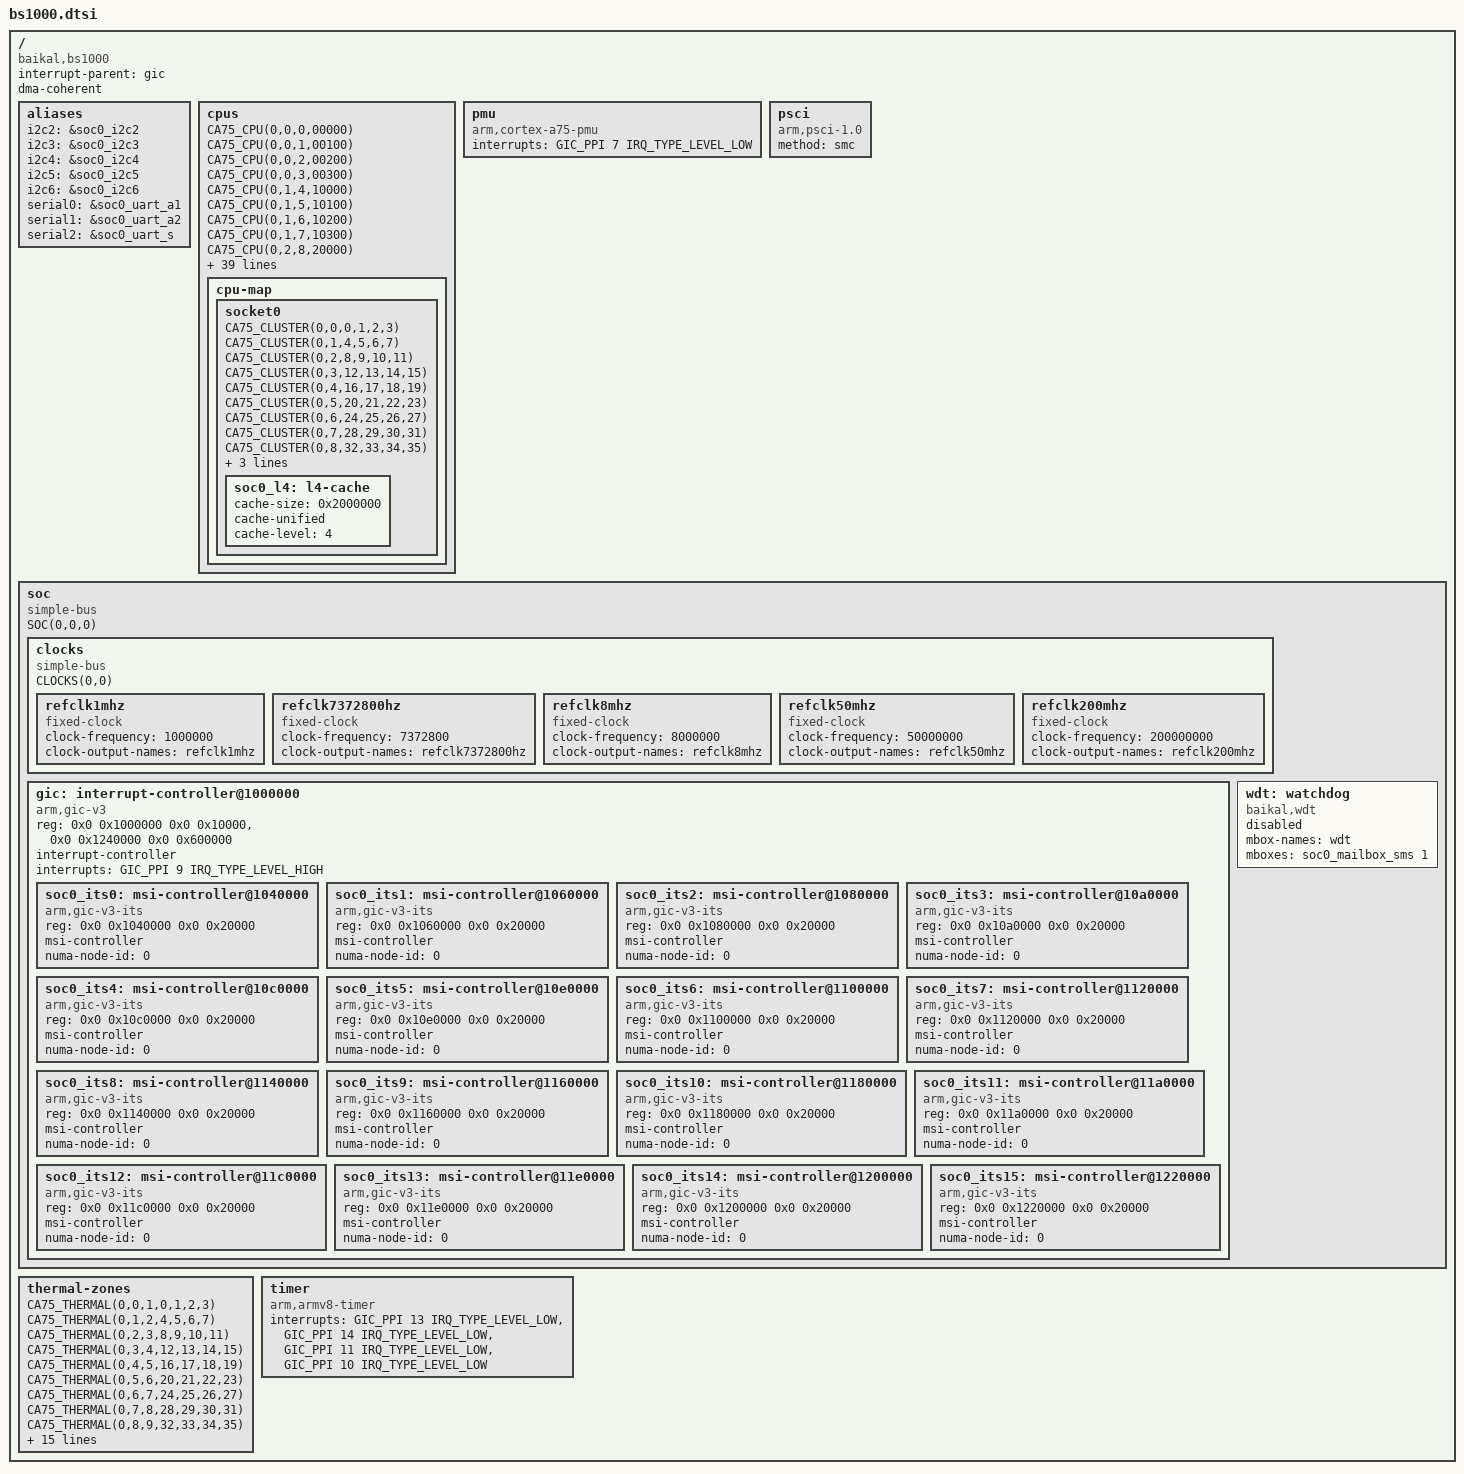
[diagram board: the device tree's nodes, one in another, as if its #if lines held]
// SPDX-License-Identifier: GPL-2.0
/*
 * Device tree include file for BE-S1000 SoC
 * Copyright (C) 2021-2025 Baikal Electronics, JSC
 */

#include <dt-bindings/gpio/gpio.h>
#include <dt-bindings/interrupt-controller/arm-gic.h>
#include <dt-bindings/thermal/thermal.h>

#define CA75_CLUSTER(chip, group, a,b,c,d)				\
	cluster##group {						\
		core0 {							\
			cpu = <&cpu##a>;				\
		};							\
		core1 {							\
			cpu = <&cpu##b>;				\
		};							\
		core2 {							\
			cpu = <&cpu##c>;				\
		};							\
		core3 {							\
			cpu = <&cpu##d>;				\
		};							\
		soc##chip##_l3_##group: l3-cache {			\
			compatible = "cache";				\
			cache-size = <0x200000>;			\
			cache-line-size = <64>;				\
			cache-sets = <2048>;				\
			cache-unified;					\
			cache-level = <3>;				\
			next-level-cache = <&soc##chip##_l4>;		\
		};							\
		cpu_opp_table##chip##group: opp_table {			\
			compatible = "operating-points-v2";		\
			opp-shared;					\
			opp-1800000000 {				\
				opp-hz = /bits/ 64 <1800000000>;	\
			};						\
			opp-1900000000 {				\
				opp-hz = /bits/ 64 <1900000000>;	\
			};						\
			opp-2000000000 {				\
				opp-hz = /bits/ 64 <2000000000>;	\
			};						\
		};							\
	}

#define CA75_CPU(chip, group, core, affinity)					\
	cpu##core: cpu@##chip##000##affinity {					\
		device_type = "cpu";						\
		compatible = "arm,cortex-a75";					\
		reg = <0x##chip 0x##affinity>;					\
		enable-method = "psci";						\
		i-cache-size = <0x10000>;					\
		i-cache-line-size = <64>;					\
		i-cache-sets = <256>;						\
		d-cache-size = <0x10000>;					\
		d-cache-line-size = <64>;					\
		d-cache-sets = <64>;						\
		next-level-cache = <&l2_##core>;				\
		operating-points-v2 = <&cpu_opp_table##chip##group>;		\
		clocks = <&soc##chip##_ca75_##group##_cmu1_pll>;		\
		numa-node-id = <chip>;						\
		#cooling-cells = <2>; /* min followed by max */			\
		l2_##core: l2-cache {						\
			compatible = "cache";					\
			cache-size = <0x80000>;					\
			cache-line-size = <64>;					\
			cache-sets = <1024>;					\
			cache-unified;						\
			cache-level = <2>;					\
			next-level-cache = <&soc##chip##_l3_##group>;		\
		};								\
	}

#define CLK_TYPE_REFCLK	1 /* fout = 25 MHz or 100 MHz		*/
#define CLK_TYPE_PLL	2 /* fout = 2 * fref * NF / (NR * OD)	*/
#define CLK_TYPE_CLKCH	3 /* fout = fref / (VAL_CLKDIV + 1)	*/
#define CLK_TYPE_CLKEN	4 /* fout = fref / DIV_VAL		*/
#define CLK_TYPE_CLKDIV	5 /* fout = fref / 2^(DIV_VAL - 1)	*/

#define STRINGIFY2( x) #x
#define STRINGIFY(x) STRINGIFY2(x)

#define CA75_CLOCKS(chip, group, hbase, lbase)						\
	/* pll */									\
	soc##chip##_ca75_##group##_cmu0_pll:						\
	soc##chip##_ca75_##group##_cmu0_pll {						\
		compatible = "baikal,bs1000-cmu";					\
		reg = <0x##hbase 0x##lbase>;						\
		type = <CLK_TYPE_PLL>;							\
		clocks = <&soc##chip##_clk_ref>;					\
		#clock-cells = <0>;							\
		clock-output-names = "ca75_pll0";					\
	};										\
	soc##chip##_ca75_##group##_cmu1_pll:						\
	soc##chip##_ca75_##group##_cmu1_pll {						\
		compatible = "baikal,bs1000-cmu";					\
		reg = <0x##hbase (0x##lbase + 0x10000)>;				\
		type = <CLK_TYPE_PLL>;							\
		clocks = <&soc##chip##_clk_ref>;					\
		#clock-cells = <0>;							\
		clock-output-names = "ca75_pll1";					\
		clock-frequency = <2000000000>;						\
	};										\
	/* clkch */									\
	soc##chip##_ca75_##group##_cmu0_clkch:						\
	soc##chip##_ca75_##group##_cmu0_clkch {						\
		compatible = "baikal,bs1000-cmu";					\
		reg = <0x##hbase (0x##lbase + 0x100)>;					\
		type = <CLK_TYPE_CLKCH>;						\
		clocks = <&soc##chip##_ca75_##group##_cmu0_pll>;			\
		#clock-cells = <1>;							\
		clock-output-names =							\
			"sclk",		/* 0 */						\
			"periph",	/* 1 */						\
			"pclk",		/* 2 */						\
			"at",		/* 3 */						\
			"gic",		/* 4 */						\
			"cfg_int",	/* 5 */						\
			"cfg_out",	/* 6 */						\
			"bisr",		/* 7 */						\
			"crp";		/* 8 */						\
	};										\
	/* clken */									\
	soc##chip##_ca75_##group##_cmu0_en0:						\
	soc##chip##_ca75_##group##_cmu0_en0 {						\
		compatible = "baikal,bs1000-cmu";					\
		reg = <0x##hbase (0x##lbase + 0x500)>;					\
		type = <CLK_TYPE_CLKEN>;						\
		clocks = <&soc##chip##_ca75_##group##_cmu0_clkch 0>; /* "sclk" */	\
		#clock-cells = <0>;							\
		clock-output-names = "clken";						\
	};										\
	soc##chip##_ca75_##group##_cmu0_en1:						\
	soc##chip##_ca75_##group##_cmu0_en1 {						\
		compatible = "baikal,bs1000-cmu";					\
		reg = <0x##hbase (0x##lbase + 0x510)>;					\
		type = <CLK_TYPE_CLKEN>;						\
		clocks = <&soc##chip##_ca75_##group##_cmu0_clkch 1>; /* "periph" */	\
		#clock-cells = <1>;							\
		clock-output-names =							\
			"cntclken",	/* 0 */						\
			"tsclken";	/* 1 */						\
	};										\
	/* core */									\
	soc##chip##_ca75_##group##_cmu1_core:						\
	soc##chip##_ca75_##group##_cmu1_core {						\
		compatible = "baikal,bs1000-cmu";					\
		reg = <0x##hbase (0x##lbase + 0x10020)>;				\
		type = <CLK_TYPE_CLKDIV>;						\
		clocks = <&soc##chip##_ca75_##group##_cmu1_pll>;			\
		#clock-cells = <1>;							\
		clock-output-names =							\
			"core0",	/* 0 */						\
			"core1",	/* 1 */						\
			"core2",	/* 2 */						\
			"core3";	/* 3 */						\
		clock-frequency =							\
			<2000000000>,							\
			<2000000000>,							\
			<2000000000>,							\
			<2000000000>;							\
	}

#define MM_CLOCKS(chip, mm, num, hbase, lbase, ...)			\
	/* pll */							\
	soc##chip##_##mm##_cmu##num##_pll:				\
	soc##chip##_##mm##_cmu##num##_pll {				\
		compatible = "baikal,bs1000-cmu";			\
		reg = <0x##hbase 0x##lbase>;				\
		type = <CLK_TYPE_PLL>;					\
		clocks = <&soc##chip##_clk_ref>;			\
		#clock-cells = <0>;					\
		clock-output-names = STRINGIFY(mm ## pll); 		\
	};								\
	/* clkch */							\
	soc##chip##_##mm##_cmu##num##_clkch:				\
	soc##chip##_##mm##_cmu##num##_clkch {				\
		compatible = "baikal,bs1000-cmu";			\
		reg = <0x##hbase (0x##lbase + 0x20)>;			\
		type = <CLK_TYPE_CLKCH>;				\
		clocks = <&soc##chip##_##mm##_cmu##num##_pll>;		\
		#clock-cells = <1>;					\
		clock-output-names = __VA_ARGS__;			\
	}

#define CLOCKS(chip, hbase)							\
	/* CLK_REF */								\
	soc##chip##_clk_ref: soc##chip##_clk_ref {				\
		compatible = "baikal,bs1000-cmu";				\
		reg = <0x##hbase 0xdead>;					\
		type = <CLK_TYPE_REFCLK>;					\
		#clock-cells = <0>;						\
		clock-output-names = "clk_ref";					\
	};									\
										\
	CA75_CLOCKS(chip, 0, hbase, 04000000);					\
	CA75_CLOCKS(chip, 1, hbase, 08000000);					\
	CA75_CLOCKS(chip, 2, hbase, 0c000000);					\
	CA75_CLOCKS(chip, 3, hbase, 10000000);					\
	CA75_CLOCKS(chip, 4, hbase, 14000000);					\
	CA75_CLOCKS(chip, 5, hbase, 18000000);					\
	CA75_CLOCKS(chip, 6, hbase, 1c000000);					\
	CA75_CLOCKS(chip, 7, hbase, 20000000);					\
	CA75_CLOCKS(chip, 8, hbase, 24000000);					\
	CA75_CLOCKS(chip, 9, hbase, 28000000);					\
	CA75_CLOCKS(chip, 10,hbase, 2c000000);					\
	CA75_CLOCKS(chip, 11,hbase, 30000000);					\
										\
	/* PCIe */								\
	MM_CLOCKS(chip, pci_0,, hbase, 38000000,				\
		"nic_cfg0m_ssa_x16p0s",		/* 0  */			\
		"nic_cfg1m_ssa_x8p1s",		/* 1  */			\
		"nic_cfg2m_mmu_tcus",		/* 2  */			\
		"nic_cfg3m_ssa_apbs",		/* 3  */			\
		"nic_cfg4m_nic_slv_gpvs",	/* 4  */			\
		"nic_slv0m_ssa_x16p0s",		/* 5  */			\
		"nic_slv1m_ssa_x8p1s",		/* 6  */			\
		"ssa_x16p0m_nic_mstr0s",	/* 7  */			\
		"ssa_x8p1m_nic_mstr1s",		/* 8  */			\
		"nic_mstrm_mmu_tbu0s",		/* 9  */			\
		"a4sw_intern",			/* 10 */			\
		"phy_ref",			/* 11 */			\
		"ssa_aux",			/* 12 */			\
		"ahb2axim_axi2ahbs",		/* 13 */			\
		"ahb2ahbm_outp_ahbs",		/* 14 */			\
		"ssa_x16p0m_cxlas"		/* 15 */			\
	);									\
	MM_CLOCKS(chip, pci_1,, hbase, 3c000000,				\
		"nic_cfg0m_ssa_x16p0s",		/* 0  */			\
		"nic_cfg1m_ssa_x8p1s",		/* 1  */			\
		"nic_cfg2m_mmu_tcus",		/* 2  */			\
		"nic_cfg3m_ssa_apbs",		/* 3  */			\
		"nic_cfg4m_nic_slv_gpvs",	/* 4  */			\
		"nic_slv0m_ssa_x16p0s",		/* 5  */			\
		"nic_slv1m_ssa_x8p1s",		/* 6  */			\
		"ssa_x16p0m_nic_mstr0s",	/* 7  */			\
		"ssa_x8p1m_nic_mstr1s",		/* 8  */			\
		"nic_mstrm_mmu_tbu0s",		/* 9  */			\
		"a4sw_intern",			/* 10 */			\
		"phy_ref",			/* 11 */			\
		"ssa_aux",			/* 12 */			\
		"ahb2axim_axi2ahbs",		/* 13 */			\
		"ahb2ahbm_outp_ahbs",		/* 14 */			\
		"ssa_x16p0m_cxlas"		/* 15 */			\
	);									\
	MM_CLOCKS(chip, pci_2,, hbase, 44000000,				\
		"a", /* 0 */							\
		"b"  /* 1 */							\
	);									\
	MM_CLOCKS(chip, pci_3,, hbase, 48000000,				\
		"a", /* 0 */							\
		"b"  /* 1 */							\
	);									\
	MM_CLOCKS(chip, pci_4,, hbase, 4c000000,				\
		"a", /* 0 */							\
		"b"  /* 1 */							\
	);									\
										\
	/* DDR */								\
	MM_CLOCKS(chip, ddr_0,, hbase, 50000000,				\
		"ddr_ctrl_phy",		/* 0 */					\
		"ddr_axi_slv",		/* 1 */					\
		"ddr_apb_slv"		/* 2 */					\
	);									\
	MM_CLOCKS(chip, ddr_1,, hbase, 54000000,				\
		"ddr_ctrl_phy",		/* 0 */					\
		"ddr_axi_slv",		/* 1 */					\
		"ddr_apb_slv",		/* 2 */					\
		"axi_ext_cfg",		/* 3 */					\
		"axi_middle_cfg",	/* 4 */					\
		"axi_top_cfg",		/* 5 */					\
		"axi_bottom_cfg"	/* 6 */					\
	);									\
	MM_CLOCKS(chip, ddr_2,, hbase, 58000000,				\
		"ddr_ctrl_phy",		/* 0 */					\
		"ddr_axi_slv",		/* 1 */					\
		"ddr_apb_slv"		/* 2 */					\
	);									\
	MM_CLOCKS(chip, ddr_3,, hbase, 60000000,				\
		"ddr_ctrl_phy",		/* 0 */					\
		"ddr_axi_slv",		/* 1 */					\
		"ddr_apb_slv"		/* 2 */					\
	);									\
	MM_CLOCKS(chip, ddr_4,, hbase, 64000000,				\
		"ddr_ctrl_phy",		/* 0 */					\
		"ddr_axi_slv",		/* 1 */					\
		"ddr_apb_slv",		/* 2 */					\
		"axi_ext_cfg",		/* 3 */					\
		"axi_middle_cfg",	/* 4 */					\
		"axi_top_cfg",		/* 5 */					\
		"axi_bottom_cfg"	/* 6 */					\
	);									\
	MM_CLOCKS(chip, ddr_5,, hbase, 68000000,				\
		"ddr_ctrl_phy",		/* 0 */					\
		"ddr_axi_slv",		/* 1 */					\
		"ddr_apb_slv"		/* 2 */					\
	);									\
										\
	/* System Control */							\
	MM_CLOCKS(chip, sc, 0, hbase, 00400000,					\
		"cmn",			/* 0 */					\
		"cmn_cs"		/* 1 */					\
	);									\
	MM_CLOCKS(chip, sc, 1, hbase, 00410000,					\
		"apb_cfg",		/* 0  */				\
		"scp_efuse",		/* 1  */				\
		"scp_ext_cfg",		/* 2  */				\
		"scp_apb_spi",		/* 3  */				\
		"scp_uart",		/* 4  */				\
		"scp_gpio8_x16",	/* 5, additional divisor by 16 */	\
		"scp_spi",		/* 6  */				\
		"scp_smbus_i2c0",	/* 7  */				\
		"scp_smbus_i2c1",	/* 8  */				\
		"gmac1_apb",		/* 9  */				\
		"gmac1_axi",		/* 10 */				\
		"gmac2_apb",		/* 11 */				\
		"gmac2_axi",		/* 12 */				\
		"usb_h",		/* 13 */				\
		"usb_ohci",		/* 14 */				\
		"lsp_apb",		/* 15 */				\
		"lsp_gpio_x16",		/* 16, additional divisor by 16 */	\
		"lsp_uart",		/* 17 */				\
		"lsp_uart_arm1",	/* 18 */				\
		"lsp_uart_arm2",	/* 19 */				\
		"lsp_spi1",		/* 20 */				\
		"lsp_spi2",		/* 21 */				\
		"lsp_espi",		/* 22 */				\
		"lsp_smbus_i2c2",	/* 23 */				\
		"lsp_smbus_i2c3",	/* 24 */				\
		"lsp_smbus_i2c4",	/* 25 */				\
		"lsp_smbus_i2c5",	/* 26 */				\
		"lsp_smbus_i2c6",	/* 27 */				\
		"lsp_timer1",		/* 28 */				\
		"lsp_timer2",		/* 29 */				\
		"lsp_timer3",		/* 30 */				\
		"lsp_timer4",		/* 31 */				\
		"lsp_wdt_x16",		/* 32, additional divisor by 16 */	\
		"tcu",			/* 33 */				\
		"sc_axi_cfg",		/* 34 */				\
		"ca75_ahb_cfg"		/* 35 */				\
	);									\
	MM_CLOCKS(chip, sc, 2, hbase, 00420000,					\
		"scp",			/* 0  */				\
		"gmac1_ptp",		/* 1  */				\
		"gmac1_txx2",		/* 2  */				\
		"gmac2_ptp",		/* 3  */				\
		"gmac2_txx2",		/* 4  */				\
		"gic_distr",		/* 5  */				\
		"dbg",			/* 6  */				\
		"cnt_valueb",		/* 7  */				\
		"ts_valueb",		/* 8  */				\
		"lpd",			/* 9  */				\
		"tbu",			/* 10 */				\
		"hs_cfg",		/* 11 */				\
		"scp_bisr"		/* 12 */				\
	)

#define SOC(chip, hbase, spi_base)									\
	soc##chip##_mailbox_sms: mailbox@##hbase##00210000 {						\
		compatible = "baikal,baikal-mbox-sms";							\
		reg = <0x##hbase 0x210000 0x0 0x10000>;							\
		interrupts = <GIC_SPI (spi_base + 33) IRQ_TYPE_LEVEL_HIGH>;				\
		#mbox-cells = <1>;									\
		status = "disabled";									\
	};												\
													\
	sram@##hbase##0001fd00 {									\
		compatible = "mmio-sram";								\
		reg = <0x##hbase 0x1fd00 0x0 0x100>;							\
													\
		#address-cells = <1>;									\
		#size-cells = <1>;									\
		ranges = <0 0x##hbase 0x1fd00 0x100>;							\
													\
		soc##chip##_shmem_scmi_a2p: scmi-shmem@0 {						\
			compatible = "arm,scmi-shmem";							\
			reg = <0x0 0x80>;								\
		};											\
													\
		soc##chip##_shmem_scmi_p2a: scmi-shmem@80 {						\
			compatible = "arm,scmi-shmem";							\
			reg = <0x80 0x80>;								\
		};											\
	};												\
													\
	soc##chip##_mailbox_scmi_a2p: mailbox@##hbase##00240000 {					\
		compatible = "baikal,baikal-mbox-scmi";							\
		reg = <0x##hbase 0x240000 0x0 0x10000>;							\
		interrupts = <GIC_SPI (spi_base + 36) IRQ_TYPE_LEVEL_HIGH>;				\
		#mbox-cells = <1>;									\
		status = "disabled";									\
	};												\
													\
	soc##chip##_mailbox_scmi_p2a: mailbox@##hbase##00250000 {					\
		compatible = "baikal,baikal-mbox-scmi";							\
		reg = <0x##hbase 0x250000 0x0 0x10000>;							\
		interrupts = <GIC_SPI (spi_base + 37) IRQ_TYPE_LEVEL_HIGH>;				\
		#mbox-cells = <1>;									\
		status = "disabled";									\
	};												\
													\
	scmi##chip {											\
		compatible = "baikal,scmi", "arm,scmi";							\
		mboxes = <&soc##chip##_mailbox_scmi_a2p 0 &soc##chip##_mailbox_scmi_p2a 0>;		\
		mbox-names = "tx", "rx";								\
		shmem = <&soc##chip##_shmem_scmi_a2p &soc##chip##_shmem_scmi_p2a>;			\
		arm,max-rx-timeout-ms = <300>;								\
		#address-cells = <1>;									\
		#size-cells = <0>;									\
		numa-node-id = <chip>;									\
													\
		soc##chip##_scmi_base_ext: protocol@80 {						\
			reg = <0x80>;									\
			sms = <&soc##chip##_mailbox_sms 2>;						\
			#thermal-sensor-cells = <1>;							\
		};											\
	};												\
													\
	soc##chip##_sc_smmu: iommu@##hbase##00900000 {							\
		compatible = "arm,smmu-v3";								\
		reg = <0x##hbase 0x900000 0x0 0x60000>;							\
		interrupts = <GIC_SPI (spi_base + 41) IRQ_TYPE_EDGE_RISING>,				\
			     <GIC_SPI (spi_base + 42) IRQ_TYPE_EDGE_RISING>,				\
			     <GIC_SPI (spi_base + 44) IRQ_TYPE_EDGE_RISING>,				\
			     <GIC_SPI (spi_base + 46) IRQ_TYPE_EDGE_RISING>;				\
		interrupt-names = "eventq", "priq", "cmdq-sync", "gerror";				\
		#iommu-cells = <1>;									\
		baikal,bs1000-bypass-gic;								\
		status = "disabled";									\
	};												\
													\
	soc##chip##_ohci: usb@##hbase##00a00000 {							\
		compatible = "generic-ohci";								\
		reg = <0x##hbase 0xa00000 0x0 0x1000>;							\
		interrupts = <GIC_SPI (spi_base + 78) IRQ_TYPE_LEVEL_HIGH>;				\
		dr_mode = "host";									\
		clocks = <&soc##chip##_sc_cmu1_clkch 13>,						\
			 <&soc##chip##_sc_cmu1_clkch 14>;						\
		clock-names = "ohci_hclk", "ohci_clk48";						\
		iommus = <&soc##chip##_sc_smmu 0x2>;							\
		status = "disabled";									\
	};												\
													\
	soc##chip##_ehci: usb@##hbase##00a10000 {							\
		compatible = "generic-ehci";								\
		reg = <0x##hbase 0xa10000 0x0 0x1000>;							\
		interrupts = <GIC_SPI (spi_base + 82) IRQ_TYPE_LEVEL_HIGH>;				\
		dr_mode = "host";									\
		clocks = <&soc##chip##_sc_cmu1_clkch 13>;						\
		clock-names = "ehci_hclk";								\
		iommus = <&soc##chip##_sc_smmu 0xc>;							\
		status = "disabled";									\
	};												\
													\
	soc##chip##_gmac0: ethernet@##hbase##00a20000 {							\
		compatible = "baikal,bs1000-gmac";							\
		reg = <0x##hbase 0xa20000 0x0 0x10000>;							\
		interrupts = <GIC_SPI (spi_base + 76) IRQ_TYPE_LEVEL_HIGH>;				\
		interrupt-names = "macirq";								\
		max-speed = <1000>;									\
		clocks = <&soc##chip##_sc_cmu1_clkch 9>,						\
			 <&soc##chip##_sc_cmu2_clkch 1>,						\
			 <&soc##chip##_sc_cmu2_clkch 2>;						\
		clock-names = "stmmaceth", "ptp_ref", "tx2_clk";					\
		status = "disabled";									\
													\
		soc##chip##_mdio0: mdio {								\
			compatible = "snps,dwmac-mdio";							\
			#address-cells = <1>;								\
			#size-cells = <0>;								\
		};											\
	};												\
													\
	soc##chip##_gmac1: ethernet@##hbase##00a30000 {							\
		compatible = "baikal,bs1000-gmac";							\
		reg = <0x##hbase 0xa30000 0x0 0x10000>;							\
		interrupts = <GIC_SPI (spi_base + 77) IRQ_TYPE_LEVEL_HIGH>;				\
		interrupt-names = "macirq";								\
		max-speed = <1000>;									\
		clocks = <&soc##chip##_sc_cmu1_clkch 11>,						\
			 <&soc##chip##_sc_cmu2_clkch 3>,						\
			 <&soc##chip##_sc_cmu2_clkch 4>;						\
		clock-names = "stmmaceth", "ptp_ref", "tx2_clk";					\
		status = "disabled";									\
													\
		soc##chip##_mdio1: mdio {								\
			compatible = "snps,dwmac-mdio";							\
			#address-cells = <1>;								\
			#size-cells = <0>;								\
		};											\
	};												\
													\
	soc##chip##_uart_a1: serial@##hbase##00c00000 {							\
		compatible = "arm,pl011", "arm,primecell";						\
		reg = <0x##hbase 0xc00000 0x0 0x1000>;							\
		interrupts = <GIC_SPI (spi_base + 61) IRQ_TYPE_LEVEL_HIGH>;				\
		clocks = <&refclk8mhz>, <&refclk200mhz>;						\
		clock-names = "uartclk", "apb_pclk";							\
		status = "disabled";									\
	};												\
													\
	soc##chip##_uart_a2: serial@##hbase##00c10000 {							\
		compatible = "arm,pl011", "arm,primecell";						\
		reg = <0x##hbase 0xc10000 0x0 0x1000>;							\
		interrupts = <GIC_SPI (spi_base + 62) IRQ_TYPE_LEVEL_HIGH>;				\
		clocks = <&refclk8mhz>, <&refclk200mhz>;						\
		clock-names = "uartclk", "apb_pclk";							\
		status = "disabled";									\
	};												\
													\
	soc##chip##_qspi1: spi@##hbase##00c20000 {							\
		compatible = "snps,dw-apb-ssi";								\
		reg = <0x##hbase 0xc20000 0x0 0x1000>;							\
		#address-cells = <1>;									\
		#size-cells = <0>;									\
		interrupts = <GIC_SPI (spi_base + 63) IRQ_TYPE_LEVEL_HIGH>;				\
		clocks = <&refclk200mhz>;								\
		num-cs = <2>;										\
		status = "disabled";									\
	};												\
													\
	soc##chip##_qspi2: spi@##hbase##00c30000 {							\
		compatible = "snps,dw-apb-ssi";								\
		reg = <0x##hbase 0xc30000 0x0 0x1000>;							\
		#address-cells = <1>;									\
		#size-cells = <0>;									\
		interrupts = <GIC_SPI (spi_base + 64) IRQ_TYPE_LEVEL_HIGH>;				\
		clocks = <&refclk200mhz>;								\
		num-cs = <2>;										\
		status = "disabled";									\
	};												\
													\
	soc##chip##_espi: spi@##hbase##00c40000 {							\
		compatible = "baikal,bs1000-espi";							\
		reg = <0x##hbase 0xc40000 0x0 0x1000>;							\
		#address-cells = <1>;									\
		#size-cells = <0>;									\
		interrupts = <GIC_SPI (spi_base + 70) IRQ_TYPE_LEVEL_HIGH>;				\
		clocks = <&refclk200mhz>;								\
		status = "disabled";									\
	};												\
													\
	soc##chip##_gpio32: gpio@##hbase##00c50000 {							\
		compatible = "snps,dw-apb-gpio";							\
		reg = <0x##hbase 0xc50000 0x0 0x1000>;							\
		#address-cells = <1>;									\
		#size-cells = <0>;									\
		clocks = <&refclk1mhz>;									\
		status = "disabled";									\
													\
		soc##chip##_porta: gpio-controller@0 {							\
			compatible = "snps,dw-apb-gpio-port";						\
			gpio-controller;								\
			#gpio-cells = <2>;								\
			ngpios = <32>;									\
			reg = <0>;									\
			interrupt-controller;								\
			#interrupt-cells = <2>;								\
			interrupts = <GIC_SPI (spi_base + 54) IRQ_TYPE_LEVEL_HIGH>;			\
		};											\
	};												\
													\
	soc##chip##_gpio16: gpio@##hbase##00c60000 {							\
		compatible = "snps,dw-apb-gpio";							\
		reg = <0x##hbase 0xc60000 0x0 0x1000>;							\
		#address-cells = <1>;									\
		#size-cells = <0>;									\
		clocks = <&refclk1mhz>;									\
		status = "disabled";									\
													\
		soc##chip##_portb: gpio-controller@0 {							\
			compatible = "snps,dw-apb-gpio-port";						\
			gpio-controller;								\
			#gpio-cells = <2>;								\
			ngpios = <16>;									\
			reg = <0>;									\
			interrupt-controller;								\
			#interrupt-cells = <2>;								\
			interrupts = <GIC_SPI (spi_base + 51) IRQ_TYPE_LEVEL_HIGH>;			\
		};											\
	};												\
													\
	soc##chip##_gpio8_1: gpio@##hbase##00c70000 {							\
		compatible = "snps,dw-apb-gpio";							\
		reg = <0x##hbase 0xc70000 0x0 0x1000>;							\
		#address-cells = <1>;									\
		#size-cells = <0>;									\
		clocks = <&refclk1mhz>;									\
		status = "disabled";									\
													\
		soc##chip##_portc: gpio-controller@0 {							\
			compatible = "snps,dw-apb-gpio-port";						\
			gpio-controller;								\
			#gpio-cells = <2>;								\
			ngpios = <8>;									\
			reg = <0>;									\
			interrupt-controller;								\
			#interrupt-cells = <2>;								\
			interrupts = <GIC_SPI (spi_base + 52) IRQ_TYPE_LEVEL_HIGH>;			\
		};											\
	};												\
													\
	soc##chip##_gpio8_2: gpio@##hbase##00c80000 {							\
		compatible = "snps,dw-apb-gpio";							\
		reg = <0x##hbase 0xc80000 0x0 0x1000>;							\
		#address-cells = <1>;									\
		#size-cells = <0>;									\
		clocks = <&refclk1mhz>;									\
		status = "disabled";									\
													\
		soc##chip##_portd: gpio-controller@0 {							\
			compatible = "snps,dw-apb-gpio-port";						\
			gpio-controller;								\
			#gpio-cells = <2>;								\
			ngpios = <8>;									\
			reg = <0>;									\
			interrupt-controller;								\
			#interrupt-cells = <2>;								\
			interrupts = <GIC_SPI (spi_base + 53) IRQ_TYPE_LEVEL_HIGH>;			\
		};											\
	};												\
													\
	soc##chip##_i2c2: i2c@##hbase##00c90000 {							\
		compatible = "snps,designware-i2c";							\
		reg = <0x##hbase 0xc90000 0x0 0x1000>;							\
		#address-cells = <1>;									\
		#size-cells = <0>;									\
		interrupts = <GIC_SPI (spi_base + 65) IRQ_TYPE_LEVEL_HIGH>;				\
		i2c-sda-hold-time-ns = <500>;								\
		clock-frequency = <400000>;								\
		clocks = <&refclk200mhz>;								\
		clock-names = "ref";									\
		status = "disabled";									\
	};												\
													\
	soc##chip##_i2c3: i2c@##hbase##00ca0000 {							\
		compatible = "snps,designware-i2c";							\
		reg = <0x##hbase 0xca0000 0x0 0x1000>;							\
		#address-cells = <1>;									\
		#size-cells = <0>;									\
		interrupts = <GIC_SPI (spi_base + 66) IRQ_TYPE_LEVEL_HIGH>;				\
		i2c-sda-hold-time-ns = <500>;								\
		clock-frequency = <400000>;								\
		clocks = <&refclk200mhz>;								\
		clock-names = "ref";									\
		status = "disabled";									\
	};												\
													\
	soc##chip##_i2c4: i2c@##hbase##00cb0000 {							\
		compatible = "snps,designware-i2c";							\
		reg = <0x##hbase 0xcb0000 0x0 0x1000>;							\
		#address-cells = <1>;									\
		#size-cells = <0>;									\
		interrupts = <GIC_SPI (spi_base + 67) IRQ_TYPE_LEVEL_HIGH>;				\
		i2c-sda-hold-time-ns = <500>;								\
		clock-frequency = <400000>;								\
		clocks = <&refclk200mhz>;								\
		clock-names = "ref";									\
		status = "disabled";									\
	};												\
													\
	soc##chip##_i2c5: i2c@##hbase##00cc0000 {							\
		compatible = "snps,designware-i2c";							\
		reg = <0x##hbase 0xcc0000 0x0 0x1000>;							\
		#address-cells = <1>;									\
		#size-cells = <0>;									\
		interrupts = <GIC_SPI (spi_base + 68) IRQ_TYPE_LEVEL_HIGH>;				\
		i2c-sda-hold-time-ns = <500>;								\
		clock-frequency = <400000>;								\
		clocks = <&refclk200mhz>;								\
		clock-names = "ref";									\
		status = "disabled";									\
	};												\
													\
	soc##chip##_i2c6: i2c@##hbase##00cd0000 {							\
		compatible = "snps,designware-i2c";							\
		reg = <0x##hbase 0xcd0000 0x0 0x1000>;							\
		#address-cells = <1>;									\
		#size-cells = <0>;									\
		interrupts = <GIC_SPI (spi_base + 69) IRQ_TYPE_LEVEL_HIGH>;				\
		i2c-sda-hold-time-ns = <500>;								\
		clock-frequency = <400000>;								\
		clocks = <&refclk200mhz>;								\
		clock-names = "ref";									\
		status = "disabled";									\
	};												\
													\
	soc##chip##_wdt: watchdog@##hbase##00ce0000 {							\
		compatible = "snps,dw-wdt";								\
		reg = <0x##hbase 0xce0000 0x0 0x1000>;							\
		interrupts = <GIC_SPI (spi_base + 59) IRQ_TYPE_LEVEL_HIGH>;				\
		clocks = <&refclk1mhz>;									\
		clock-names = "tclk";									\
		snps,watchdog-tops = <0x000000ff 0x000001ff 0x000003ff 0x000007ff			\
				      0x0000ffff 0x0001ffff 0x0003ffff 0x0007ffff			\
				      0x000fffff 0x001fffff 0x003fffff 0x007fffff			\
				      0x00ffffff 0x01ffffff 0x03ffffff 0x07ffffff>;			\
		status = "disabled";									\
	};												\
													\
	soc##chip##_timer1: timer@##hbase##00cf0000 {							\
		compatible = "snps,dw-apb-timer";							\
		reg = <0x##hbase 0xcf0000 0x0 0x14>;							\
		interrupts = <GIC_SPI (spi_base + 55) IRQ_TYPE_LEVEL_HIGH>;				\
		clocks = <&refclk50mhz>;								\
		clock-names = "timer";									\
		status = "disabled";									\
	};												\
													\
	soc##chip##_timer2: timer@##hbase##00cf0014 {							\
		compatible = "snps,dw-apb-timer";							\
		reg = <0x##hbase 0xcf0014 0x0 0x14>;							\
		interrupts = <GIC_SPI (spi_base + 56) IRQ_TYPE_LEVEL_HIGH>;				\
		clocks = <&refclk50mhz>;								\
		clock-names = "timer";									\
		status = "disabled";									\
	};												\
													\
	soc##chip##_timer3: timer@##hbase##00cf0028 {							\
		compatible = "snps,dw-apb-timer";							\
		reg = <0x##hbase 0xcf0028 0x0 0x14>;							\
		interrupts = <GIC_SPI (spi_base + 57) IRQ_TYPE_LEVEL_HIGH>;				\
		clocks = <&refclk50mhz>;								\
		clock-names = "timer";									\
		status = "disabled";									\
	};												\
													\
	soc##chip##_timer4: timer@##hbase##00cf003c {							\
		compatible = "snps,dw-apb-timer";							\
		reg = <0x##hbase 0xcf003c 0x0 0x14>;							\
		interrupts = <GIC_SPI (spi_base + 58) IRQ_TYPE_LEVEL_HIGH>;				\
		clocks = <&refclk50mhz>;								\
		clock-names = "timer";									\
		status = "disabled";									\
	};												\
													\
	soc##chip##_uart_s: serial@##hbase##00e00000 {							\
		compatible = "snps,dw-apb-uart";							\
		reg = <0x##hbase 0xe00000 0x0 0x100>;							\
		interrupts = <GIC_SPI (spi_base + 60) IRQ_TYPE_LEVEL_HIGH>;				\
		reg-shift = <2>;									\
		reg-io-width = <4>;									\
		clocks = <&refclk7372800hz>, <&refclk200mhz>;						\
		clock-names = "baudclk", "apb_pclk";							\
		status = "disabled";									\
	};												\
													\
	soc##chip##_pcie0_smmu: iommu@##hbase##38800000 {						\
		compatible = "arm,smmu-v3";								\
		reg = <0x##hbase 0x38800000 0x0 0x60000>;						\
		interrupts = <GIC_SPI (spi_base + 150) IRQ_TYPE_LEVEL_HIGH>,				\
			     <GIC_SPI (spi_base + 151) IRQ_TYPE_LEVEL_HIGH>,				\
			     <GIC_SPI (spi_base + 153) IRQ_TYPE_LEVEL_HIGH>,				\
			     <GIC_SPI (spi_base + 155) IRQ_TYPE_LEVEL_HIGH>;				\
		interrupt-names = "eventq", "priq", "cmdq-sync", "gerror";				\
		#iommu-cells = <1>;									\
		status = "disabled";									\
	};												\
													\
	soc##chip##_pcie0_p0: pcie@##hbase##39000000 {							\
		compatible = "baikal,bs1000-pcie";							\
		reg = <0x##hbase 0x39000000 0x0 0x300000>,						\
		      <0x##hbase 0x39300000 0x0 0x800>,							\
		      <0x##hbase 0x39380000 0x0 0x800>,							\
		      <0x##hbase 0x38d40000 0x0 0x100>,							\
		      <(0x##hbase + 0x73f) 0xf0000000 0x0 0x10000000>;					\
		reg-names = "dbi", "atu", "dma", "apb", "config";					\
		device_type = "pci";									\
		bus-range = <0x0 0xff>;									\
		interrupts = <GIC_SPI (spi_base + 129) IRQ_TYPE_LEVEL_HIGH>,				\
		             <GIC_SPI (spi_base + 130) IRQ_TYPE_LEVEL_HIGH>,				\
		             <GIC_SPI (spi_base + 131) IRQ_TYPE_LEVEL_HIGH>,				\
		             <GIC_SPI (spi_base + 132) IRQ_TYPE_LEVEL_HIGH>,				\
		             <GIC_SPI (spi_base + 133) IRQ_TYPE_LEVEL_HIGH>,				\
		             <GIC_SPI (spi_base + 134) IRQ_TYPE_LEVEL_HIGH>,				\
		             <GIC_SPI (spi_base + 135) IRQ_TYPE_LEVEL_HIGH>,				\
		             <GIC_SPI (spi_base + 136) IRQ_TYPE_LEVEL_HIGH>,				\
		             <GIC_SPI (spi_base + 145) IRQ_TYPE_LEVEL_HIGH>,				\
			     <GIC_SPI (spi_base + 147) IRQ_TYPE_LEVEL_HIGH>;				\
		interrupt-names = "dma0", "dma1", "dma2", "dma3",                                       \
		                  "dma4", "dma5", "dma6", "dma7",                                       \
		                  "intr", "msi";							\
		#interrupt-cells = <1>;									\
		#address-cells = <3>;									\
		#size-cells = <2>;									\
		ranges = <0x81000000 0x00 0x00000000 (0x##hbase + 0x73f) 0xe0000000 0x00 0x100000>,	\
			 <0x82000000 0x00 0x40000000 (0x##hbase + 0x73f) 0x40000000 0x00 0x40000000>,	\
			 <0x82000000 0x01 0x00000000 (0x##hbase + 0x701) 0x00000000 0x3e 0x40000000>;	\
		num-viewport = <4>;									\
		msi-parent = <&soc##chip##_its0 0x0>;							\
		msi-map = <0x0 &soc##chip##_its0 0x0 0x10000>;						\
		iommu-map = <0x0 &soc##chip##_pcie0_smmu 0x0 0x10000>;					\
		numa-node-id = <chip>;									\
		status = "disabled";									\
	};												\
													\
	soc##chip##_pcie0_p0_ep: pcie-ep@##hbase##39000000 {						\
		compatible = "baikal,bs1000-pcie-ep";							\
		reg = <0x##hbase 0x39000000 0x0 0x300000>,						\
		      <0x##hbase 0x39300000 0x0 0x800>,							\
		      <0x##hbase 0x38d40000 0x0 0x100>,							\
		      <(0x##hbase + 0x700) 0x00000000 0x1 0x00000000>;					\
		reg-names = "dbi", "atu", "apb", "addr_space";						\
		interrupts = <GIC_SPI (spi_base + 129) IRQ_TYPE_LEVEL_HIGH>,				\
		             <GIC_SPI (spi_base + 130) IRQ_TYPE_LEVEL_HIGH>,				\
		             <GIC_SPI (spi_base + 131) IRQ_TYPE_LEVEL_HIGH>,				\
		             <GIC_SPI (spi_base + 132) IRQ_TYPE_LEVEL_HIGH>,				\
		             <GIC_SPI (spi_base + 133) IRQ_TYPE_LEVEL_HIGH>,				\
		             <GIC_SPI (spi_base + 134) IRQ_TYPE_LEVEL_HIGH>,				\
		             <GIC_SPI (spi_base + 135) IRQ_TYPE_LEVEL_HIGH>,				\
		             <GIC_SPI (spi_base + 136) IRQ_TYPE_LEVEL_HIGH>;				\
		interrupt-names = "dma0", "dma1", "dma2", "dma3",                                       \
		                  "dma4", "dma5", "dma6", "dma7";                                       \
		num-ib-windows = <4>;									\
		num-ob-windows = <4>;									\
		numa-node-id = <chip>;									\
		status = "disabled";									\
	};												\
													\
	soc##chip##_pcie0_p1: pcie@##hbase##39400000 {							\
		compatible = "baikal,bs1000-pcie";							\
		reg = <0x##hbase 0x39400000 0x0 0x300000>,						\
		      <0x##hbase 0x39700000 0x0 0x800>,							\
		      <0x##hbase 0x39780000 0x0 0x800>,							\
		      <0x##hbase 0x38d41000 0x0 0x100>,							\
		      <(0x##hbase + 0x77f) 0xf0000000 0x0 0x10000000>;					\
		reg-names = "dbi", "atu", "dma", "apb", "config";					\
		device_type = "pci";									\
		bus-range = <0x0 0xff>;									\
		interrupts = <GIC_SPI (spi_base + 137) IRQ_TYPE_LEVEL_HIGH>,				\
		             <GIC_SPI (spi_base + 138) IRQ_TYPE_LEVEL_HIGH>,				\
		             <GIC_SPI (spi_base + 139) IRQ_TYPE_LEVEL_HIGH>,				\
		             <GIC_SPI (spi_base + 140) IRQ_TYPE_LEVEL_HIGH>,				\
		             <GIC_SPI (spi_base + 141) IRQ_TYPE_LEVEL_HIGH>,				\
		             <GIC_SPI (spi_base + 142) IRQ_TYPE_LEVEL_HIGH>,				\
		             <GIC_SPI (spi_base + 143) IRQ_TYPE_LEVEL_HIGH>,				\
		             <GIC_SPI (spi_base + 144) IRQ_TYPE_LEVEL_HIGH>,				\
		             <GIC_SPI (spi_base + 146) IRQ_TYPE_LEVEL_HIGH>,				\
			     <GIC_SPI (spi_base + 148) IRQ_TYPE_LEVEL_HIGH>;				\
		interrupt-names = "dma0", "dma1", "dma2", "dma3",                                       \
		                  "dma4", "dma5", "dma6", "dma7",                                       \
		                  "intr", "msi";							\
		#interrupt-cells = <1>;									\
		#address-cells = <3>;									\
		#size-cells = <2>;									\
		ranges = <0x81000000 0x00 0x00100000 (0x##hbase + 0x77f) 0xe0100000 0x00 0x100000>,	\
			 <0x82000000 0x00 0x40000000 (0x##hbase + 0x77f) 0x40000000 0x00 0x40000000>,	\
			 <0x82000000 0x40 0x00000000 (0x##hbase + 0x740) 0x00000000 0x3f 0x40000000>;	\
		num-viewport = <4>;									\
		msi-parent = <&soc##chip##_its0 0x10000>;						\
		msi-map = <0x0 &soc##chip##_its0 0x10000 0x10000>;					\
		iommu-map = <0x0 &soc##chip##_pcie0_smmu 0x10000 0x10000>;				\
		numa-node-id = <chip>;									\
		status = "disabled";									\
	};												\
													\
	soc##chip##_pcie1_smmu: iommu@##hbase##3c800000 {						\
		compatible = "arm,smmu-v3";								\
		reg = <0x##hbase 0x3c800000 0x0 0x60000>;						\
		interrupts = <GIC_SPI (spi_base + 193) IRQ_TYPE_LEVEL_HIGH>,				\
			     <GIC_SPI (spi_base + 194) IRQ_TYPE_LEVEL_HIGH>,				\
			     <GIC_SPI (spi_base + 196) IRQ_TYPE_LEVEL_HIGH>,				\
			     <GIC_SPI (spi_base + 198) IRQ_TYPE_LEVEL_HIGH>;				\
		interrupt-names = "eventq", "priq", "cmdq-sync", "gerror";				\
		#iommu-cells = <1>;									\
		status = "disabled";									\
	};												\
													\
	soc##chip##_pcie1_p0: pcie@##hbase##3d000000 {							\
		compatible = "baikal,bs1000-pcie";							\
		reg = <0x##hbase 0x3d000000 0x0 0x300000>,						\
		      <0x##hbase 0x3d300000 0x0 0x800>,							\
		      <0x##hbase 0x3d380000 0x0 0x800>,							\
		      <0x##hbase 0x3cd40000 0x0 0x100>,							\
		      <(0x##hbase + 0x7bf) 0xf0000000 0x0 0x10000000>;					\
		reg-names = "dbi", "atu", "dma", "apb", "config";					\
		device_type = "pci";									\
		bus-range = <0x0 0xff>;									\
		interrupts = <GIC_SPI (spi_base + 172) IRQ_TYPE_LEVEL_HIGH>,				\
		             <GIC_SPI (spi_base + 173) IRQ_TYPE_LEVEL_HIGH>,				\
		             <GIC_SPI (spi_base + 174) IRQ_TYPE_LEVEL_HIGH>,				\
		             <GIC_SPI (spi_base + 175) IRQ_TYPE_LEVEL_HIGH>,				\
		             <GIC_SPI (spi_base + 176) IRQ_TYPE_LEVEL_HIGH>,				\
		             <GIC_SPI (spi_base + 177) IRQ_TYPE_LEVEL_HIGH>,				\
		             <GIC_SPI (spi_base + 178) IRQ_TYPE_LEVEL_HIGH>,				\
		             <GIC_SPI (spi_base + 179) IRQ_TYPE_LEVEL_HIGH>,				\
		             <GIC_SPI (spi_base + 188) IRQ_TYPE_LEVEL_HIGH>,				\
			     <GIC_SPI (spi_base + 190) IRQ_TYPE_LEVEL_HIGH>;				\
		interrupt-names = "dma0", "dma1", "dma2", "dma3",                                       \
		                  "dma4", "dma5", "dma6", "dma7",                                       \
		                  "intr", "msi";							\
		#interrupt-cells = <1>;									\
		#address-cells = <3>;									\
		#size-cells = <2>;									\
		ranges = <0x81000000 0x00 0x00200000 (0x##hbase + 0x7bf) 0xe0200000 0x00 0x100000>,	\
			 <0x82000000 0x00 0x40000000 (0x##hbase + 0x7bf) 0x40000000 0x00 0x40000000>,	\
			 <0x82000000 0x01 0x00000000 (0x##hbase + 0x781) 0x00000000 0x3e 0x40000000>;	\
		num-viewport = <4>;									\
		msi-parent = <&soc##chip##_its2 0x0>;							\
		msi-map = <0x0 &soc##chip##_its2 0x0 0x10000>;						\
		iommu-map = <0x0 &soc##chip##_pcie1_smmu 0x0 0x10000>;					\
		numa-node-id = <chip>;									\
		status = "disabled";									\
	};												\
													\
	soc##chip##_pcie1_p0_ep: pcie-ep@##hbase##3d000000 {						\
		compatible = "baikal,bs1000-pcie-ep";							\
		reg = <0x##hbase 0x3d000000 0x0 0x300000>,						\
		      <0x##hbase 0x3d300000 0x0 0x800>,							\
		      <0x##hbase 0x3cd40000 0x0 0x100>,							\
		      <(0x##hbase + 0x780) 0x00000000 0x1 0x00000000>;					\
		reg-names = "dbi", "atu", "apb", "addr_space";						\
		interrupts = <GIC_SPI (spi_base + 172) IRQ_TYPE_LEVEL_HIGH>,				\
		             <GIC_SPI (spi_base + 173) IRQ_TYPE_LEVEL_HIGH>,				\
		             <GIC_SPI (spi_base + 174) IRQ_TYPE_LEVEL_HIGH>,				\
		             <GIC_SPI (spi_base + 175) IRQ_TYPE_LEVEL_HIGH>,				\
		             <GIC_SPI (spi_base + 176) IRQ_TYPE_LEVEL_HIGH>,				\
		             <GIC_SPI (spi_base + 177) IRQ_TYPE_LEVEL_HIGH>,				\
		             <GIC_SPI (spi_base + 178) IRQ_TYPE_LEVEL_HIGH>,				\
		             <GIC_SPI (spi_base + 179) IRQ_TYPE_LEVEL_HIGH>;				\
		interrupt-names = "dma0", "dma1", "dma2", "dma3",                                       \
		                  "dma4", "dma5", "dma6", "dma7";                                       \
		num-ib-windows = <4>;									\
		num-ob-windows = <4>;									\
		numa-node-id = <chip>;									\
		status = "disabled";									\
	};												\
													\
	soc##chip##_pcie1_p1: pcie@##hbase##3d400000 {							\
		compatible = "baikal,bs1000-pcie";							\
		reg = <0x##hbase 0x3d400000 0x0 0x300000>,						\
		      <0x##hbase 0x3d700000 0x0 0x800>,							\
		      <0x##hbase 0x3d780000 0x0 0x800>,							\
		      <0x##hbase 0x3cd41000 0x0 0x100>,							\
		      <(0x##hbase + 0x7ff) 0xf0000000 0x0 0x10000000>;					\
		reg-names = "dbi", "atu", "dma", "apb", "config";					\
		device_type = "pci";									\
		bus-range = <0x0 0xff>;									\
		interrupts = <GIC_SPI (spi_base + 180) IRQ_TYPE_LEVEL_HIGH>,				\
		             <GIC_SPI (spi_base + 181) IRQ_TYPE_LEVEL_HIGH>,				\
		             <GIC_SPI (spi_base + 182) IRQ_TYPE_LEVEL_HIGH>,				\
		             <GIC_SPI (spi_base + 183) IRQ_TYPE_LEVEL_HIGH>,				\
		             <GIC_SPI (spi_base + 184) IRQ_TYPE_LEVEL_HIGH>,				\
		             <GIC_SPI (spi_base + 185) IRQ_TYPE_LEVEL_HIGH>,				\
		             <GIC_SPI (spi_base + 186) IRQ_TYPE_LEVEL_HIGH>,				\
		             <GIC_SPI (spi_base + 187) IRQ_TYPE_LEVEL_HIGH>,				\
		             <GIC_SPI (spi_base + 189) IRQ_TYPE_LEVEL_HIGH>,				\
			     <GIC_SPI (spi_base + 191) IRQ_TYPE_LEVEL_HIGH>;				\
		interrupt-names = "dma0", "dma1", "dma2", "dma3",                                       \
		                  "dma4", "dma5", "dma6", "dma7",                                       \
		                  "intr", "msi";							\
		#interrupt-cells = <1>;									\
		#address-cells = <3>;									\
		#size-cells = <2>;									\
		ranges = <0x81000000 0x00 0x00300000 (0x##hbase + 0x7ff) 0xe0300000 0x00 0x100000>,	\
			 <0x82000000 0x00 0x40000000 (0x##hbase + 0x7ff) 0x40000000 0x00 0x40000000>,	\
			 <0x82000000 0x40 0x00000000 (0x##hbase + 0x7c0) 0x00000000 0x3f 0x40000000>;	\
		num-viewport = <4>;									\
		msi-parent = <&soc##chip##_its2 0x10000>;						\
		msi-map = <0x0 &soc##chip##_its2 0x10000 0x10000>;					\
		iommu-map = <0x0 &soc##chip##_pcie1_smmu 0x10000 0x10000>;				\
		numa-node-id = <chip>;									\
		status = "disabled";									\
	};												\
													\
	soc##chip##_pcie2_smmu: iommu@##hbase##44800000 {						\
		compatible = "arm,smmu-v3";								\
		reg = <0x##hbase 0x44800000 0x0 0x60000>;						\
		interrupts = <GIC_SPI (spi_base + 107) IRQ_TYPE_LEVEL_HIGH>,				\
			     <GIC_SPI (spi_base + 108) IRQ_TYPE_LEVEL_HIGH>,				\
			     <GIC_SPI (spi_base + 110) IRQ_TYPE_LEVEL_HIGH>,				\
			     <GIC_SPI (spi_base + 112) IRQ_TYPE_LEVEL_HIGH>;				\
		interrupt-names = "eventq", "priq", "cmdq-sync", "gerror";				\
		#iommu-cells = <1>;									\
		status = "disabled";									\
	};												\
													\
	soc##chip##_pcie2_p0: pcie@##hbase##45000000 {							\
		compatible = "baikal,bs1000-pcie";							\
		reg = <0x##hbase 0x45000000 0x0 0x300000>,						\
		      <0x##hbase 0x45300000 0x0 0x800>,							\
		      <0x##hbase 0x45380000 0x0 0x800>,							\
		      <0x##hbase 0x44d40000 0x0 0x100>,							\
		      <(0x##hbase + 0x53f) 0xf0000000 0x0 0x10000000>;					\
		reg-names = "dbi", "atu", "dma", "apb", "config";					\
		device_type = "pci";									\
		bus-range = <0x0 0xff>;									\
		interrupts = <GIC_SPI (spi_base + 86) IRQ_TYPE_LEVEL_HIGH>,				\
		             <GIC_SPI (spi_base + 87) IRQ_TYPE_LEVEL_HIGH>,				\
		             <GIC_SPI (spi_base + 88) IRQ_TYPE_LEVEL_HIGH>,				\
		             <GIC_SPI (spi_base + 89) IRQ_TYPE_LEVEL_HIGH>,				\
		             <GIC_SPI (spi_base + 90) IRQ_TYPE_LEVEL_HIGH>,				\
		             <GIC_SPI (spi_base + 91) IRQ_TYPE_LEVEL_HIGH>,				\
		             <GIC_SPI (spi_base + 92) IRQ_TYPE_LEVEL_HIGH>,				\
		             <GIC_SPI (spi_base + 93) IRQ_TYPE_LEVEL_HIGH>,				\
		             <GIC_SPI (spi_base + 102) IRQ_TYPE_LEVEL_HIGH>,				\
			     <GIC_SPI (spi_base + 104) IRQ_TYPE_LEVEL_HIGH>;				\
		interrupt-names = "dma0", "dma1", "dma2", "dma3",                                       \
		                  "dma4", "dma5", "dma6", "dma7",                                       \
		                  "intr", "msi";							\
		#interrupt-cells = <1>;									\
		#address-cells = <3>;									\
		#size-cells = <2>;									\
		ranges = <0x81000000 0x00 0x00400000 (0x##hbase + 0x53f) 0xe0400000 0x00 0x100000>,	\
			 <0x82000000 0x00 0x40000000 (0x##hbase + 0x53f) 0x40000000 0x00 0x40000000>,	\
			 <0x82000000 0x01 0x00000000 (0x##hbase + 0x501) 0x00000000 0x3e 0x40000000>;	\
		num-viewport = <4>;									\
		msi-parent = <&soc##chip##_its4 0x0>;							\
		msi-map = <0x0 &soc##chip##_its4 0x0 0x10000>;						\
		iommu-map = <0x0 &soc##chip##_pcie2_smmu 0x0 0x10000>;					\
		numa-node-id = <chip>;									\
		status = "disabled";									\
	};												\
													\
	soc##chip##_pcie2_p0_ep: pcie-ep@##hbase##45000000 {						\
		compatible = "baikal,bs1000-pcie-ep";							\
		reg = <0x##hbase 0x45000000 0x0 0x300000>,						\
		      <0x##hbase 0x45300000 0x0 0x800>,							\
		      <0x##hbase 0x44d40000 0x0 0x100>,							\
		      <(0x##hbase + 0x500) 0x00000000 0x1 0x00000000>;					\
		reg-names = "dbi", "atu", "apb", "addr_space";						\
		interrupts = <GIC_SPI (spi_base + 86) IRQ_TYPE_LEVEL_HIGH>,				\
		             <GIC_SPI (spi_base + 87) IRQ_TYPE_LEVEL_HIGH>,				\
		             <GIC_SPI (spi_base + 88) IRQ_TYPE_LEVEL_HIGH>,				\
		             <GIC_SPI (spi_base + 89) IRQ_TYPE_LEVEL_HIGH>,				\
		             <GIC_SPI (spi_base + 90) IRQ_TYPE_LEVEL_HIGH>,				\
		             <GIC_SPI (spi_base + 91) IRQ_TYPE_LEVEL_HIGH>,				\
		             <GIC_SPI (spi_base + 92) IRQ_TYPE_LEVEL_HIGH>,				\
		             <GIC_SPI (spi_base + 93) IRQ_TYPE_LEVEL_HIGH>;				\
		interrupt-names = "dma0", "dma1", "dma2", "dma3",                                       \
		                  "dma4", "dma5", "dma6", "dma7";                                       \
		num-ib-windows = <4>;									\
		num-ob-windows = <4>;									\
		numa-node-id = <chip>;									\
		status = "disabled";									\
	};												\
													\
	soc##chip##_pcie2_p1: pcie@##hbase##45400000 {							\
		compatible = "baikal,bs1000-pcie";							\
		reg = <0x##hbase 0x45400000 0x0 0x300000>,						\
		      <0x##hbase 0x45700000 0x0 0x800>,							\
		      <0x##hbase 0x45780000 0x0 0x800>,							\
		      <0x##hbase 0x44d41000 0x0 0x100>,							\
		      <(0x##hbase + 0x57f) 0xf0000000 0x0 0x10000000>;					\
		reg-names = "dbi", "atu", "dma", "apb", "config";					\
		device_type = "pci";									\
		bus-range = <0x0 0xff>;									\
		interrupts = <GIC_SPI (spi_base + 94) IRQ_TYPE_LEVEL_HIGH>,				\
		             <GIC_SPI (spi_base + 95) IRQ_TYPE_LEVEL_HIGH>,				\
		             <GIC_SPI (spi_base + 96) IRQ_TYPE_LEVEL_HIGH>,				\
		             <GIC_SPI (spi_base + 97) IRQ_TYPE_LEVEL_HIGH>,				\
		             <GIC_SPI (spi_base + 98) IRQ_TYPE_LEVEL_HIGH>,				\
		             <GIC_SPI (spi_base + 99) IRQ_TYPE_LEVEL_HIGH>,				\
		             <GIC_SPI (spi_base + 100) IRQ_TYPE_LEVEL_HIGH>,				\
		             <GIC_SPI (spi_base + 101) IRQ_TYPE_LEVEL_HIGH>,				\
		             <GIC_SPI (spi_base + 103) IRQ_TYPE_LEVEL_HIGH>,				\
			     <GIC_SPI (spi_base + 105) IRQ_TYPE_LEVEL_HIGH>;				\
		interrupt-names = "dma0", "dma1", "dma2", "dma3",                                       \
		                  "dma4", "dma5", "dma6", "dma7",                                       \
		                  "intr", "msi";							\
		#interrupt-cells = <1>;									\
		#address-cells = <3>;									\
		#size-cells = <2>;									\
		ranges = <0x81000000 0x00 0x00500000 (0x##hbase + 0x57f) 0xe0500000 0x00 0x100000>,	\
			 <0x82000000 0x00 0x40000000 (0x##hbase + 0x57f) 0x40000000 0x00 0x40000000>,	\
			 <0x82000000 0x40 0x00000000 (0x##hbase + 0x540) 0x00000000 0x3f 0x40000000>;	\
		num-viewport = <4>;									\
		msi-parent = <&soc##chip##_its4 0x10000>;						\
		msi-map = <0x0 &soc##chip##_its4 0x10000 0x10000>;					\
		iommu-map = <0x0 &soc##chip##_pcie2_smmu 0x10000 0x10000>;				\
		numa-node-id = <chip>;									\
		status = "disabled";									\
	};												\
													\
	soc##chip##_pcie3_smmu: iommu@##hbase##48800000 {						\
		compatible = "arm,smmu-v3";								\
		reg = <0x##hbase 0x48800000 0x0 0xc0000>;						\
		interrupts = <GIC_SPI (spi_base + 258) IRQ_TYPE_LEVEL_HIGH>,				\
			     <GIC_SPI (spi_base + 259) IRQ_TYPE_LEVEL_HIGH>,				\
			     <GIC_SPI (spi_base + 261) IRQ_TYPE_LEVEL_HIGH>,				\
			     <GIC_SPI (spi_base + 263) IRQ_TYPE_LEVEL_HIGH>;				\
		interrupt-names = "eventq", "priq", "cmdq-sync", "gerror";				\
		#iommu-cells = <1>;									\
		status = "disabled";									\
	};												\
													\
	soc##chip##_pcie3_p0: pcie@##hbase##49000000 {							\
		compatible = "baikal,bs1000-pcie";							\
		reg = <0x##hbase 0x49000000 0x0 0x300000>,						\
		      <0x##hbase 0x49300000 0x0 0x800>,							\
		      <0x##hbase 0x49380000 0x0 0x800>,							\
		      <0x##hbase 0x48d40000 0x0 0x100>,							\
		      <(0x##hbase + 0x43f) 0xf0000000 0x0 0x10000000>;					\
		reg-names = "dbi", "atu", "dma", "apb", "config";					\
		device_type = "pci";									\
		bus-range = <0x0 0xff>;									\
		interrupts = <GIC_SPI (spi_base + 217) IRQ_TYPE_LEVEL_HIGH>,				\
		             <GIC_SPI (spi_base + 218) IRQ_TYPE_LEVEL_HIGH>,				\
		             <GIC_SPI (spi_base + 219) IRQ_TYPE_LEVEL_HIGH>,				\
		             <GIC_SPI (spi_base + 220) IRQ_TYPE_LEVEL_HIGH>,				\
		             <GIC_SPI (spi_base + 221) IRQ_TYPE_LEVEL_HIGH>,				\
		             <GIC_SPI (spi_base + 222) IRQ_TYPE_LEVEL_HIGH>,				\
		             <GIC_SPI (spi_base + 223) IRQ_TYPE_LEVEL_HIGH>,				\
		             <GIC_SPI (spi_base + 224) IRQ_TYPE_LEVEL_HIGH>,				\
		             <GIC_SPI (spi_base + 249) IRQ_TYPE_LEVEL_HIGH>,				\
			     <GIC_SPI (spi_base + 253) IRQ_TYPE_LEVEL_HIGH>;				\
		interrupt-names = "dma0", "dma1", "dma2", "dma3",                                       \
		                  "dma4", "dma5", "dma6", "dma7",                                       \
		                  "intr", "msi";							\
		#interrupt-cells = <1>;									\
		#address-cells = <3>;									\
		#size-cells = <2>;									\
		ranges = <0x81000000 0x00 0x00600000 (0x##hbase + 0x43f) 0xe0600000 0x00 0x100000>,	\
			 <0x82000000 0x00 0x40000000 (0x##hbase + 0x43f) 0x40000000 0x00 0x40000000>,	\
			 <0x82000000 0x01 0x00000000 (0x##hbase + 0x401) 0x00000000 0x3e 0x40000000>;	\
		num-viewport = <4>;									\
		msi-parent = <&soc##chip##_its6 0x0>;							\
		msi-map = <0x0 &soc##chip##_its6 0x0 0x10000>;						\
		iommu-map = <0x0 &soc##chip##_pcie3_smmu 0x0 0x10000>;					\
		numa-node-id = <chip>;									\
		status = "disabled";									\
	};												\
													\
	soc##chip##_pcie3_p1: pcie@##hbase##49400000 {							\
		compatible = "baikal,bs1000-pcie";							\
		reg = <0x##hbase 0x49400000 0x0 0x300000>,						\
		      <0x##hbase 0x49700000 0x0 0x800>,							\
		      <0x##hbase 0x49780000 0x0 0x800>,							\
		      <0x##hbase 0x48d41000 0x0 0x100>,							\
		      <(0x##hbase + 0x47f) 0xf0000000 0x0 0x10000000>;					\
		reg-names = "dbi", "atu", "dma", "apb", "config";					\
		device_type = "pci";									\
		bus-range = <0x0 0xff>;									\
		interrupts = <GIC_SPI (spi_base + 225) IRQ_TYPE_LEVEL_HIGH>,				\
		             <GIC_SPI (spi_base + 226) IRQ_TYPE_LEVEL_HIGH>,				\
		             <GIC_SPI (spi_base + 227) IRQ_TYPE_LEVEL_HIGH>,				\
		             <GIC_SPI (spi_base + 228) IRQ_TYPE_LEVEL_HIGH>,				\
		             <GIC_SPI (spi_base + 229) IRQ_TYPE_LEVEL_HIGH>,				\
		             <GIC_SPI (spi_base + 230) IRQ_TYPE_LEVEL_HIGH>,				\
		             <GIC_SPI (spi_base + 231) IRQ_TYPE_LEVEL_HIGH>,				\
		             <GIC_SPI (spi_base + 232) IRQ_TYPE_LEVEL_HIGH>,				\
		             <GIC_SPI (spi_base + 250) IRQ_TYPE_LEVEL_HIGH>,				\
			     <GIC_SPI (spi_base + 254) IRQ_TYPE_LEVEL_HIGH>;				\
		interrupt-names = "dma0", "dma1", "dma2", "dma3",                                       \
		                  "dma4", "dma5", "dma6", "dma7",                                       \
		                  "intr", "msi";							\
		#interrupt-cells = <1>;									\
		#address-cells = <3>;									\
		#size-cells = <2>;									\
		ranges = <0x81000000 0x00 0x00700000 (0x##hbase + 0x47f) 0xe0700000 0x00 0x100000>,	\
			 <0x82000000 0x00 0x40000000 (0x##hbase + 0x47f) 0x40000000 0x00 0x40000000>,	\
			 <0x82000000 0x40 0x00000000 (0x##hbase + 0x440) 0x00000000 0x3f 0x40000000>;	\
		num-viewport = <4>;									\
		msi-parent = <&soc##chip##_its7 0x10000>;						\
		msi-map = <0x0 &soc##chip##_its7 0x10000 0x10000>;					\
		iommu-map = <0x0 &soc##chip##_pcie3_smmu 0x10000 0x10000>;				\
		numa-node-id = <chip>;									\
		status = "disabled";									\
	};												\
													\
	soc##chip##_pcie3_p2: pcie@##hbase##49800000 {							\
		compatible = "baikal,bs1000-pcie";							\
		reg = <0x##hbase 0x49800000 0x0 0x300000>,						\
		      <0x##hbase 0x49b00000 0x0 0x800>,							\
		      <0x##hbase 0x49b80000 0x0 0x800>,							\
		      <0x##hbase 0x48d42000 0x0 0x100>,							\
		      <(0x##hbase + 0x4bf) 0xf0000000 0x0 0x10000000>;					\
		reg-names = "dbi", "atu", "dma", "apb", "config";					\
		device_type = "pci";									\
		bus-range = <0x0 0xff>;									\
		interrupts = <GIC_SPI (spi_base + 233) IRQ_TYPE_LEVEL_HIGH>,				\
		             <GIC_SPI (spi_base + 234) IRQ_TYPE_LEVEL_HIGH>,				\
		             <GIC_SPI (spi_base + 235) IRQ_TYPE_LEVEL_HIGH>,				\
		             <GIC_SPI (spi_base + 236) IRQ_TYPE_LEVEL_HIGH>,				\
		             <GIC_SPI (spi_base + 237) IRQ_TYPE_LEVEL_HIGH>,				\
		             <GIC_SPI (spi_base + 238) IRQ_TYPE_LEVEL_HIGH>,				\
		             <GIC_SPI (spi_base + 239) IRQ_TYPE_LEVEL_HIGH>,				\
		             <GIC_SPI (spi_base + 240) IRQ_TYPE_LEVEL_HIGH>,				\
		             <GIC_SPI (spi_base + 251) IRQ_TYPE_LEVEL_HIGH>,				\
			     <GIC_SPI (spi_base + 255) IRQ_TYPE_LEVEL_HIGH>;				\
		interrupt-names = "dma0", "dma1", "dma2", "dma3",                                       \
		                  "dma4", "dma5", "dma6", "dma7",                                       \
		                  "intr", "msi";							\
		#interrupt-cells = <1>;									\
		#address-cells = <3>;									\
		#size-cells = <2>;									\
		ranges = <0x81000000 0x00 0x00800000 (0x##hbase + 0x4bf) 0xe0800000 0x00 0x100000>,	\
			 <0x82000000 0x00 0x40000000 (0x##hbase + 0x4bf) 0x40000000 0x00 0x40000000>,	\
			 <0x82000000 0x80 0x00000000 (0x##hbase + 0x480) 0x00000000 0x3f 0x40000000>;	\
		num-viewport = <4>;									\
		msi-parent = <&soc##chip##_its8 0x20000>;						\
		msi-map = <0x0 &soc##chip##_its8 0x20000 0x10000>;					\
		iommu-map = <0x0 &soc##chip##_pcie3_smmu 0x20000 0x10000>;				\
		numa-node-id = <chip>;									\
		status = "disabled";									\
	};												\
													\
	soc##chip##_pcie3_p3: pcie@##hbase##49c00000 {							\
		compatible = "baikal,bs1000-pcie";							\
		reg = <0x##hbase 0x49c00000 0x0 0x300000>,						\
		      <0x##hbase 0x49f00000 0x0 0x800>,							\
		      <0x##hbase 0x49f80000 0x0 0x800>,							\
		      <0x##hbase 0x48d43000 0x0 0x100>,							\
		      <(0x##hbase + 0x4ff) 0xf0000000 0x0 0x10000000>;					\
		reg-names = "dbi", "atu", "dma", "apb", "config";					\
		device_type = "pci";									\
		bus-range = <0x0 0xff>;									\
		interrupts = <GIC_SPI (spi_base + 241) IRQ_TYPE_LEVEL_HIGH>,				\
		             <GIC_SPI (spi_base + 242) IRQ_TYPE_LEVEL_HIGH>,				\
		             <GIC_SPI (spi_base + 243) IRQ_TYPE_LEVEL_HIGH>,				\
		             <GIC_SPI (spi_base + 244) IRQ_TYPE_LEVEL_HIGH>,				\
		             <GIC_SPI (spi_base + 245) IRQ_TYPE_LEVEL_HIGH>,				\
		             <GIC_SPI (spi_base + 246) IRQ_TYPE_LEVEL_HIGH>,				\
		             <GIC_SPI (spi_base + 247) IRQ_TYPE_LEVEL_HIGH>,				\
		             <GIC_SPI (spi_base + 248) IRQ_TYPE_LEVEL_HIGH>,				\
		             <GIC_SPI (spi_base + 252) IRQ_TYPE_LEVEL_HIGH>,				\
			     <GIC_SPI (spi_base + 256) IRQ_TYPE_LEVEL_HIGH>;				\
		interrupt-names = "dma0", "dma1", "dma2", "dma3",                                       \
		                  "dma4", "dma5", "dma6", "dma7",                                       \
		                  "intr", "msi";							\
		#interrupt-cells = <1>;									\
		#address-cells = <3>;									\
		#size-cells = <2>;									\
		ranges = <0x81000000 0x00 0x00900000 (0x##hbase + 0x4ff) 0xe0900000 0x00 0x100000>,	\
			 <0x82000000 0x00 0x40000000 (0x##hbase + 0x4ff) 0x40000000 0x00 0x40000000>,	\
			 <0x82000000 0xc0 0x00000000 (0x##hbase + 0x4c0) 0x00000000 0x3f 0x40000000>;	\
		num-viewport = <4>;									\
		msi-parent = <&soc##chip##_its9 0x30000>;						\
		msi-map = <0x0 &soc##chip##_its9 0x30000 0x10000>;					\
		iommu-map = <0x0 &soc##chip##_pcie3_smmu 0x30000 0x10000>;				\
		numa-node-id = <chip>;									\
		status = "disabled";									\
	};												\
													\
	soc##chip##_pcie4_smmu: iommu@##hbase##4c800000 {						\
		compatible = "arm,smmu-v3";								\
		reg = <0x##hbase 0x4c800000 0x0 0xc0000>;						\
		interrupts = <GIC_SPI (spi_base + 327) IRQ_TYPE_LEVEL_HIGH>,				\
			     <GIC_SPI (spi_base + 328) IRQ_TYPE_LEVEL_HIGH>,				\
			     <GIC_SPI (spi_base + 330) IRQ_TYPE_LEVEL_HIGH>,				\
			     <GIC_SPI (spi_base + 332) IRQ_TYPE_LEVEL_HIGH>;				\
		interrupt-names = "eventq", "priq", "cmdq-sync", "gerror";				\
		#iommu-cells = <1>;									\
		status = "disabled";									\
	};												\
													\
	soc##chip##_pcie4_p0: pcie@##hbase##4d000000 {							\
		compatible = "baikal,bs1000-pcie";							\
		reg = <0x##hbase 0x4d000000 0x0 0x300000>,						\
		      <0x##hbase 0x4d300000 0x0 0x800>,							\
		      <0x##hbase 0x4d380000 0x0 0x800>,							\
		      <0x##hbase 0x4cd40000 0x0 0x100>,							\
		      <(0x##hbase + 0x63f) 0xf0000000 0x0 0x10000000>;					\
		reg-names = "dbi", "atu", "dma", "apb", "config";					\
		device_type = "pci";									\
		bus-range = <0x0 0xff>;									\
		interrupts = <GIC_SPI (spi_base + 286) IRQ_TYPE_LEVEL_HIGH>,				\
		             <GIC_SPI (spi_base + 287) IRQ_TYPE_LEVEL_HIGH>,				\
		             <GIC_SPI (spi_base + 288) IRQ_TYPE_LEVEL_HIGH>,				\
		             <GIC_SPI (spi_base + 289) IRQ_TYPE_LEVEL_HIGH>,				\
		             <GIC_SPI (spi_base + 290) IRQ_TYPE_LEVEL_HIGH>,				\
		             <GIC_SPI (spi_base + 291) IRQ_TYPE_LEVEL_HIGH>,				\
		             <GIC_SPI (spi_base + 292) IRQ_TYPE_LEVEL_HIGH>,				\
		             <GIC_SPI (spi_base + 293) IRQ_TYPE_LEVEL_HIGH>,				\
		             <GIC_SPI (spi_base + 318) IRQ_TYPE_LEVEL_HIGH>,				\
			     <GIC_SPI (spi_base + 322) IRQ_TYPE_LEVEL_HIGH>;				\
		interrupt-names = "dma0", "dma1", "dma2", "dma3",                                       \
		                  "dma4", "dma5", "dma6", "dma7",                                       \
		                  "intr", "msi";							\
		#interrupt-cells = <1>;									\
		#address-cells = <3>;									\
		#size-cells = <2>;									\
		ranges = <0x81000000 0x00 0x00a00000 (0x##hbase + 0x63f) 0xe0a00000 0x00 0x100000>,	\
			 <0x82000000 0x00 0x40000000 (0x##hbase + 0x63f) 0x40000000 0x00 0x40000000>,	\
			 <0x82000000 0x01 0x00000000 (0x##hbase + 0x601) 0x00000000 0x3e 0x40000000>;	\
		num-viewport = <4>;									\
		msi-parent = <&soc##chip##_its11 0x0>;							\
		msi-map = <0x0 &soc##chip##_its11 0x0 0x10000>;						\
		iommu-map = <0x0 &soc##chip##_pcie4_smmu 0x0 0x10000>;					\
		numa-node-id = <chip>;									\
		status = "disabled";									\
	};												\
													\
	soc##chip##_pcie4_p1: pcie@##hbase##4d400000 {							\
		compatible = "baikal,bs1000-pcie";							\
		reg = <0x##hbase 0x4d400000 0x0 0x300000>,						\
		      <0x##hbase 0x4d700000 0x0 0x800>,							\
		      <0x##hbase 0x4d780000 0x0 0x800>,							\
		      <0x##hbase 0x4cd41000 0x0 0x100>,							\
		      <(0x##hbase + 0x67f) 0xf0000000 0x0 0x10000000>;					\
		reg-names = "dbi", "atu", "dma", "apb", "config";					\
		device_type = "pci";									\
		bus-range = <0x0 0xff>;									\
		interrupts = <GIC_SPI (spi_base + 294) IRQ_TYPE_LEVEL_HIGH>,				\
		             <GIC_SPI (spi_base + 295) IRQ_TYPE_LEVEL_HIGH>,				\
		             <GIC_SPI (spi_base + 296) IRQ_TYPE_LEVEL_HIGH>,				\
		             <GIC_SPI (spi_base + 297) IRQ_TYPE_LEVEL_HIGH>,				\
		             <GIC_SPI (spi_base + 298) IRQ_TYPE_LEVEL_HIGH>,				\
		             <GIC_SPI (spi_base + 299) IRQ_TYPE_LEVEL_HIGH>,				\
		             <GIC_SPI (spi_base + 300) IRQ_TYPE_LEVEL_HIGH>,				\
		             <GIC_SPI (spi_base + 301) IRQ_TYPE_LEVEL_HIGH>,				\
		             <GIC_SPI (spi_base + 319) IRQ_TYPE_LEVEL_HIGH>,				\
			     <GIC_SPI (spi_base + 323) IRQ_TYPE_LEVEL_HIGH>;				\
		interrupt-names = "dma0", "dma1", "dma2", "dma3",                                       \
		                  "dma4", "dma5", "dma6", "dma7",                                       \
		                  "intr", "msi";							\
		#interrupt-cells = <1>;									\
		#address-cells = <3>;									\
		#size-cells = <2>;									\
		ranges = <0x81000000 0x00 0x00b00000 (0x##hbase + 0x67f) 0xe0b00000 0x00 0x100000>,	\
			 <0x82000000 0x00 0x40000000 (0x##hbase + 0x67f) 0x40000000 0x00 0x40000000>,	\
			 <0x82000000 0x40 0x00000000 (0x##hbase + 0x640) 0x00000000 0x3f 0x40000000>;	\
		num-viewport = <4>;									\
		msi-parent = <&soc##chip##_its12 0x10000>;						\
		msi-map = <0x0 &soc##chip##_its12 0x10000 0x10000>;					\
		iommu-map = <0x0 &soc##chip##_pcie4_smmu 0x10000 0x10000>;				\
		numa-node-id = <chip>;									\
		status = "disabled";									\
	};												\
													\
	soc##chip##_pcie4_p2: pcie@##hbase##4d800000 {							\
		compatible = "baikal,bs1000-pcie";							\
		reg = <0x##hbase 0x4d800000 0x0 0x300000>,						\
		      <0x##hbase 0x4db00000 0x0 0x800>,							\
		      <0x##hbase 0x4db80000 0x0 0x800>,							\
		      <0x##hbase 0x4cd42000 0x0 0x100>,							\
		      <(0x##hbase + 0x6bf) 0xf0000000 0x0 0x10000000>;					\
		reg-names = "dbi", "atu", "dma", "apb", "config";					\
		device_type = "pci";									\
		bus-range = <0x0 0xff>;									\
		interrupts = <GIC_SPI (spi_base + 302) IRQ_TYPE_LEVEL_HIGH>,				\
		             <GIC_SPI (spi_base + 303) IRQ_TYPE_LEVEL_HIGH>,				\
		             <GIC_SPI (spi_base + 304) IRQ_TYPE_LEVEL_HIGH>,				\
		             <GIC_SPI (spi_base + 305) IRQ_TYPE_LEVEL_HIGH>,				\
		             <GIC_SPI (spi_base + 306) IRQ_TYPE_LEVEL_HIGH>,				\
		             <GIC_SPI (spi_base + 307) IRQ_TYPE_LEVEL_HIGH>,				\
		             <GIC_SPI (spi_base + 308) IRQ_TYPE_LEVEL_HIGH>,				\
		             <GIC_SPI (spi_base + 309) IRQ_TYPE_LEVEL_HIGH>,				\
		             <GIC_SPI (spi_base + 320) IRQ_TYPE_LEVEL_HIGH>,				\
			     <GIC_SPI (spi_base + 324) IRQ_TYPE_LEVEL_HIGH>;				\
		interrupt-names = "dma0", "dma1", "dma2", "dma3",                                       \
		                  "dma4", "dma5", "dma6", "dma7",                                       \
		                  "intr", "msi";							\
		#interrupt-cells = <1>;									\
		#address-cells = <3>;									\
		#size-cells = <2>;									\
		ranges = <0x81000000 0x00 0x00c00000 (0x##hbase + 0x6bf) 0xe0c00000 0x00 0x100000>,	\
			 <0x82000000 0x00 0x40000000 (0x##hbase + 0x6bf) 0x40000000 0x00 0x40000000>,	\
			 <0x82000000 0x80 0x00000000 (0x##hbase + 0x680) 0x00000000 0x3f 0x40000000>;	\
		num-viewport = <4>;									\
		msi-parent = <&soc##chip##_its13 0x20000>;						\
		msi-map = <0x0 &soc##chip##_its13 0x20000 0x10000>;					\
		iommu-map = <0x0 &soc##chip##_pcie4_smmu 0x20000 0x10000>;				\
		numa-node-id = <chip>;									\
		status = "disabled";									\
	};												\
													\
	soc##chip##_pcie4_p3: pcie@##hbase##4dc00000 {							\
		compatible = "baikal,bs1000-pcie";							\
		reg = <0x##hbase 0x4dc00000 0x0 0x300000>,						\
		      <0x##hbase 0x4df00000 0x0 0x800>,							\
		      <0x##hbase 0x4df80000 0x0 0x800>,							\
		      <0x##hbase 0x4cd43000 0x0 0x100>,							\
		      <(0x##hbase + 0x6ff) 0xf0000000 0x0 0x10000000>;					\
		reg-names = "dbi", "atu", "dma", "apb", "config";					\
		device_type = "pci";									\
		bus-range = <0x0 0xff>;									\
		interrupts = <GIC_SPI (spi_base + 310) IRQ_TYPE_LEVEL_HIGH>,				\
		             <GIC_SPI (spi_base + 311) IRQ_TYPE_LEVEL_HIGH>,				\
		             <GIC_SPI (spi_base + 312) IRQ_TYPE_LEVEL_HIGH>,				\
		             <GIC_SPI (spi_base + 313) IRQ_TYPE_LEVEL_HIGH>,				\
		             <GIC_SPI (spi_base + 314) IRQ_TYPE_LEVEL_HIGH>,				\
		             <GIC_SPI (spi_base + 315) IRQ_TYPE_LEVEL_HIGH>,				\
		             <GIC_SPI (spi_base + 316) IRQ_TYPE_LEVEL_HIGH>,				\
		             <GIC_SPI (spi_base + 317) IRQ_TYPE_LEVEL_HIGH>,				\
		             <GIC_SPI (spi_base + 321) IRQ_TYPE_LEVEL_HIGH>,				\
			     <GIC_SPI (spi_base + 325) IRQ_TYPE_LEVEL_HIGH>;				\
		interrupt-names = "dma0", "dma1", "dma2", "dma3",                                       \
		                  "dma4", "dma5", "dma6", "dma7",                                       \
		                  "intr", "msi";							\
		#interrupt-cells = <1>;									\
		#address-cells = <3>;									\
		#size-cells = <2>;									\
		ranges = <0x81000000 0x00 0x00d00000 (0x##hbase + 0x6ff) 0xe0d00000 0x00 0x100000>,	\
			 <0x82000000 0x00 0x40000000 (0x##hbase + 0x6ff) 0x40000000 0x00 0x40000000>,	\
			 <0x82000000 0xc0 0x00000000 (0x##hbase + 0x6c0) 0x00000000 0x3f 0x40000000>;	\
		num-viewport = <4>;									\
		msi-parent = <&soc##chip##_its14 0x30000>;						\
		msi-map = <0x0 &soc##chip##_its14 0x30000 0x10000>;					\
		iommu-map = <0x0 &soc##chip##_pcie4_smmu 0x30000 0x10000>;				\
		numa-node-id = <chip>;									\
		status = "disabled";									\
	};												\
													\
	soc##chip##_ddrc0: memory-controller@##hbase##53000000 {					\
		compatible = "baikal,bs1000-edac-mc";							\
		reg = <0x##hbase 0x53000000 0x0 0x10000>;						\
		interrupts = <GIC_SPI (spi_base + 358) IRQ_TYPE_LEVEL_HIGH>,				\
			     <GIC_SPI (spi_base + 356) IRQ_TYPE_LEVEL_HIGH>,				\
			     <GIC_SPI (spi_base + 355) IRQ_TYPE_LEVEL_HIGH>,				\
			     <GIC_SPI (spi_base + 352) IRQ_TYPE_LEVEL_HIGH>,				\
			     <GIC_SPI (spi_base + 354) IRQ_TYPE_LEVEL_HIGH>,				\
			     <GIC_SPI (spi_base + 353) IRQ_TYPE_LEVEL_HIGH>;				\
		status = "disabled";									\
	};												\
													\
	soc##chip##_ddrc1: memory-controller@##hbase##57000000 {					\
		compatible = "baikal,bs1000-edac-mc";							\
		reg = <0x##hbase 0x57000000 0x0 0x10000>;						\
		interrupts = <GIC_SPI (spi_base + 375) IRQ_TYPE_LEVEL_HIGH>,				\
			     <GIC_SPI (spi_base + 373) IRQ_TYPE_LEVEL_HIGH>,				\
			     <GIC_SPI (spi_base + 372) IRQ_TYPE_LEVEL_HIGH>,				\
			     <GIC_SPI (spi_base + 369) IRQ_TYPE_LEVEL_HIGH>,				\
			     <GIC_SPI (spi_base + 371) IRQ_TYPE_LEVEL_HIGH>,				\
			     <GIC_SPI (spi_base + 370) IRQ_TYPE_LEVEL_HIGH>;				\
		status = "disabled";									\
	};												\
													\
	soc##chip##_ddrc2: memory-controller@##hbase##5b000000 {					\
		compatible = "baikal,bs1000-edac-mc";							\
		reg = <0x##hbase 0x5b000000 0x0 0x10000>;						\
		interrupts = <GIC_SPI (spi_base + 392) IRQ_TYPE_LEVEL_HIGH>,				\
			     <GIC_SPI (spi_base + 390) IRQ_TYPE_LEVEL_HIGH>,				\
			     <GIC_SPI (spi_base + 389) IRQ_TYPE_LEVEL_HIGH>,				\
			     <GIC_SPI (spi_base + 386) IRQ_TYPE_LEVEL_HIGH>,				\
			     <GIC_SPI (spi_base + 388) IRQ_TYPE_LEVEL_HIGH>,				\
			     <GIC_SPI (spi_base + 387) IRQ_TYPE_LEVEL_HIGH>;				\
		status = "disabled";									\
	};												\
													\
	soc##chip##_ddrc3: memory-controller@##hbase##63000000 {					\
		compatible = "baikal,bs1000-edac-mc";							\
		reg = <0x##hbase 0x63000000 0x0 0x10000>;						\
		interrupts = <GIC_SPI (spi_base + 409) IRQ_TYPE_LEVEL_HIGH>,				\
			     <GIC_SPI (spi_base + 407) IRQ_TYPE_LEVEL_HIGH>,				\
			     <GIC_SPI (spi_base + 406) IRQ_TYPE_LEVEL_HIGH>,				\
			     <GIC_SPI (spi_base + 403) IRQ_TYPE_LEVEL_HIGH>,				\
			     <GIC_SPI (spi_base + 405) IRQ_TYPE_LEVEL_HIGH>,				\
			     <GIC_SPI (spi_base + 404) IRQ_TYPE_LEVEL_HIGH>;				\
		status = "disabled";									\
	};												\
													\
	soc##chip##_ddrc4: memory-controller@##hbase##67000000 {					\
		compatible = "baikal,bs1000-edac-mc";							\
		reg = <0x##hbase 0x67000000 0x0 0x10000>;						\
		interrupts = <GIC_SPI (spi_base + 426) IRQ_TYPE_LEVEL_HIGH>,				\
			     <GIC_SPI (spi_base + 424) IRQ_TYPE_LEVEL_HIGH>,				\
			     <GIC_SPI (spi_base + 423) IRQ_TYPE_LEVEL_HIGH>,				\
			     <GIC_SPI (spi_base + 420) IRQ_TYPE_LEVEL_HIGH>,				\
			     <GIC_SPI (spi_base + 422) IRQ_TYPE_LEVEL_HIGH>,				\
			     <GIC_SPI (spi_base + 421) IRQ_TYPE_LEVEL_HIGH>;				\
		status = "disabled";									\
	};												\
													\
	soc##chip##_ddrc5: memory-controller@##hbase##6b000000 {					\
		compatible = "baikal,bs1000-edac-mc";							\
		reg = <0x##hbase 0x6b000000 0x0 0x10000>;						\
		interrupts = <GIC_SPI (spi_base + 443) IRQ_TYPE_LEVEL_HIGH>,				\
			     <GIC_SPI (spi_base + 441) IRQ_TYPE_LEVEL_HIGH>,				\
			     <GIC_SPI (spi_base + 440) IRQ_TYPE_LEVEL_HIGH>,				\
			     <GIC_SPI (spi_base + 437) IRQ_TYPE_LEVEL_HIGH>,				\
			     <GIC_SPI (spi_base + 439) IRQ_TYPE_LEVEL_HIGH>,				\
			     <GIC_SPI (spi_base + 438) IRQ_TYPE_LEVEL_HIGH>;				\
		status = "disabled";									\
	}

#define CA75_THERMAL(chip, group, pvt, a,b,c,d)							\
	thermal##chip##_cluster##group {							\
		polling-delay-passive = <1000>;							\
		polling-delay = <5000>;								\
		thermal-sensors = <&soc##chip##_scmi_base_ext pvt>;				\
												\
		trips {										\
			soc##chip##_cluster##group##_alert: cluster-alert {			\
				temperature = <75000>;						\
				hysteresis = <2000>;						\
				type = "passive";						\
			};									\
			crit {									\
				temperature = <85000>;						\
				hysteresis = <2000>;						\
				type = "critical";						\
			};									\
		};										\
												\
		cooling-maps {									\
			map0 {									\
				trip = <&soc##chip##_cluster##group##_alert>;			\
				cooling-device = <&cpu##a THERMAL_NO_LIMIT THERMAL_NO_LIMIT>,	\
						 <&cpu##b THERMAL_NO_LIMIT THERMAL_NO_LIMIT>,	\
						 <&cpu##c THERMAL_NO_LIMIT THERMAL_NO_LIMIT>,	\
						 <&cpu##d THERMAL_NO_LIMIT THERMAL_NO_LIMIT>;	\
			};									\
		};										\
	}

#define PVT_THERMAL(chip, pvt)						\
	thermal##chip##_pvt##pvt {					\
		polling-delay-passive = <1000>;				\
		polling-delay = <5000>;					\
		thermal-sensors = <&soc##chip##_scmi_base_ext pvt>;	\
									\
		trips {							\
			crit {						\
				temperature = <85000>;			\
				hysteresis = <2000>;			\
				type = "critical";			\
			};						\
		};							\
	}

/ {
	compatible = "baikal,bs1000";
	#address-cells = <2>;
	#size-cells = <2>;
	interrupt-parent = <&gic>;
	dma-coherent;

	aliases {
		i2c2	= &soc0_i2c2;
		i2c3	= &soc0_i2c3;
		i2c4	= &soc0_i2c4;
		i2c5	= &soc0_i2c5;
		i2c6	= &soc0_i2c6;
		serial0	= &soc0_uart_a1;
		serial1	= &soc0_uart_a2;
		serial2	= &soc0_uart_s;
	};

	cpus {
		#address-cells = <2>;
		#size-cells = <0>;

		cpu-map {
			socket0 {
				CA75_CLUSTER(0,0,0,1,2,3);
				CA75_CLUSTER(0,1,4,5,6,7);
				CA75_CLUSTER(0,2,8,9,10,11);
				CA75_CLUSTER(0,3,12,13,14,15);
				CA75_CLUSTER(0,4,16,17,18,19);
				CA75_CLUSTER(0,5,20,21,22,23);
				CA75_CLUSTER(0,6,24,25,26,27);
				CA75_CLUSTER(0,7,28,29,30,31);
				CA75_CLUSTER(0,8,32,33,34,35);
				CA75_CLUSTER(0,9,36,37,38,39);
				CA75_CLUSTER(0,10,40,41,42,43);
				CA75_CLUSTER(0,11,44,45,46,47);

				soc0_l4: l4-cache {
					cache-size = <0x2000000>;
					cache-unified;
					cache-level = <4>;
				};
			};
		};

		CA75_CPU(0,0,0,00000);
		CA75_CPU(0,0,1,00100);
		CA75_CPU(0,0,2,00200);
		CA75_CPU(0,0,3,00300);
		CA75_CPU(0,1,4,10000);
		CA75_CPU(0,1,5,10100);
		CA75_CPU(0,1,6,10200);
		CA75_CPU(0,1,7,10300);
		CA75_CPU(0,2,8,20000);
		CA75_CPU(0,2,9,20100);
		CA75_CPU(0,2,10,20200);
		CA75_CPU(0,2,11,20300);
		CA75_CPU(0,3,12,30000);
		CA75_CPU(0,3,13,30100);
		CA75_CPU(0,3,14,30200);
		CA75_CPU(0,3,15,30300);
		CA75_CPU(0,4,16,40000);
		CA75_CPU(0,4,17,40100);
		CA75_CPU(0,4,18,40200);
		CA75_CPU(0,4,19,40300);
		CA75_CPU(0,5,20,50000);
		CA75_CPU(0,5,21,50100);
		CA75_CPU(0,5,22,50200);
		CA75_CPU(0,5,23,50300);
		CA75_CPU(0,6,24,60000);
		CA75_CPU(0,6,25,60100);
		CA75_CPU(0,6,26,60200);
		CA75_CPU(0,6,27,60300);
		CA75_CPU(0,7,28,70000);
		CA75_CPU(0,7,29,70100);
		CA75_CPU(0,7,30,70200);
		CA75_CPU(0,7,31,70300);
		CA75_CPU(0,8,32,80000);
		CA75_CPU(0,8,33,80100);
		CA75_CPU(0,8,34,80200);
		CA75_CPU(0,8,35,80300);
		CA75_CPU(0,9,36,90000);
		CA75_CPU(0,9,37,90100);
		CA75_CPU(0,9,38,90200);
		CA75_CPU(0,9,39,90300);
		CA75_CPU(0,10,40,a0000);
		CA75_CPU(0,10,41,a0100);
		CA75_CPU(0,10,42,a0200);
		CA75_CPU(0,10,43,a0300);
		CA75_CPU(0,11,44,b0000);
		CA75_CPU(0,11,45,b0100);
		CA75_CPU(0,11,46,b0200);
		CA75_CPU(0,11,47,b0300);
	};

	pmu {
		compatible = "arm,cortex-a75-pmu", "arm,armv8-pmuv3";
		interrupts = <GIC_PPI 7 IRQ_TYPE_LEVEL_LOW>;
	};

	psci {
		compatible = "arm,psci-1.0", "arm,psci-0.2";
		method = "smc";
	};

	soc {
		compatible = "simple-bus";
		#address-cells = <2>;
		#size-cells = <2>;
		ranges;

		SOC(0,0,0);

		clocks {
			compatible = "simple-bus";
			#address-cells = <2>;
			#size-cells = <0>;

			CLOCKS(0,0);

			refclk1mhz: refclk1mhz {
				compatible = "fixed-clock";
				#clock-cells = <0>;
				clock-frequency = <1000000>;
				clock-output-names = "refclk1mhz";
			};
			refclk7372800hz: refclk7372800hz {
				compatible = "fixed-clock";
				#clock-cells = <0>;
				clock-frequency = <7372800>;
				clock-output-names = "refclk7372800hz";
			};
			refclk8mhz: refclk8mhz {
				compatible = "fixed-clock";
				#clock-cells = <0>;
				clock-frequency = <8000000>;
				clock-output-names = "refclk8mhz";
			};
			refclk50mhz: refclk50mhz {
				compatible = "fixed-clock";
				#clock-cells = <0>;
				clock-frequency = <50000000>;
				clock-output-names = "refclk50mhz";
			};
			refclk200mhz: refclk200mhz {
				compatible = "fixed-clock";
				#clock-cells = <0>;
				clock-frequency = <200000000>;
				clock-output-names = "refclk200mhz";
			};
		};

		gic: interrupt-controller@1000000 {
			compatible = "arm,gic-v3";
			reg = <0x0 0x1000000 0x0 0x10000>,  /* GICD */
			      <0x0 0x1240000 0x0 0x600000>; /* GICR */
			#interrupt-cells = <3>;
			#address-cells = <2>;
			#size-cells = <2>;
			ranges;
			interrupt-controller;
			interrupts = <GIC_PPI 9 IRQ_TYPE_LEVEL_HIGH>;

			soc0_its0: msi-controller@1040000 {
				compatible = "arm,gic-v3-its";
				reg = <0x0 0x1040000 0x0 0x20000>;
				msi-controller;
				#msi-cells = <1>;
				numa-node-id = <0>;
			};
			soc0_its1: msi-controller@1060000 {
				compatible = "arm,gic-v3-its";
				reg = <0x0 0x1060000 0x0 0x20000>;
				msi-controller;
				#msi-cells = <1>;
				numa-node-id = <0>;
			};
			soc0_its2: msi-controller@1080000 {
				compatible = "arm,gic-v3-its";
				reg = <0x0 0x1080000 0x0 0x20000>;
				msi-controller;
				#msi-cells = <1>;
				numa-node-id = <0>;
			};
			soc0_its3: msi-controller@10a0000 {
				compatible = "arm,gic-v3-its";
				reg = <0x0 0x10a0000 0x0 0x20000>;
				msi-controller;
				#msi-cells = <1>;
				numa-node-id = <0>;
			};
			soc0_its4: msi-controller@10c0000 {
				compatible = "arm,gic-v3-its";
				reg = <0x0 0x10c0000 0x0 0x20000>;
				msi-controller;
				#msi-cells = <1>;
				numa-node-id = <0>;
			};
			soc0_its5: msi-controller@10e0000 {
				compatible = "arm,gic-v3-its";
				reg = <0x0 0x10e0000 0x0 0x20000>;
				msi-controller;
				#msi-cells = <1>;
				numa-node-id = <0>;
			};
			soc0_its6: msi-controller@1100000 {
				compatible = "arm,gic-v3-its";
				reg = <0x0 0x1100000 0x0 0x20000>;
				msi-controller;
				#msi-cells = <1>;
				numa-node-id = <0>;
			};
			soc0_its7: msi-controller@1120000 {
				compatible = "arm,gic-v3-its";
				reg = <0x0 0x1120000 0x0 0x20000>;
				msi-controller;
				#msi-cells = <1>;
				numa-node-id = <0>;
			};
			soc0_its8: msi-controller@1140000 {
				compatible = "arm,gic-v3-its";
				reg = <0x0 0x1140000 0x0 0x20000>;
				msi-controller;
				#msi-cells = <1>;
				numa-node-id = <0>;
			};
			soc0_its9: msi-controller@1160000 {
				compatible = "arm,gic-v3-its";
				reg = <0x0 0x1160000 0x0 0x20000>;
				msi-controller;
				#msi-cells = <1>;
				numa-node-id = <0>;
			};
			soc0_its10: msi-controller@1180000 {
				compatible = "arm,gic-v3-its";
				reg = <0x0 0x1180000 0x0 0x20000>;
				msi-controller;
				#msi-cells = <1>;
				numa-node-id = <0>;
			};
			soc0_its11: msi-controller@11a0000 {
				compatible = "arm,gic-v3-its";
				reg = <0x0 0x11a0000 0x0 0x20000>;
				msi-controller;
				#msi-cells = <1>;
				numa-node-id = <0>;
			};
			soc0_its12: msi-controller@11c0000 {
				compatible = "arm,gic-v3-its";
				reg = <0x0 0x11c0000 0x0 0x20000>;
				msi-controller;
				#msi-cells = <1>;
				numa-node-id = <0>;
			};
			soc0_its13: msi-controller@11e0000 {
				compatible = "arm,gic-v3-its";
				reg = <0x0 0x11e0000 0x0 0x20000>;
				msi-controller;
				#msi-cells = <1>;
				numa-node-id = <0>;
			};
			soc0_its14: msi-controller@1200000 {
				compatible = "arm,gic-v3-its";
				reg = <0x0 0x1200000 0x0 0x20000>;
				msi-controller;
				#msi-cells = <1>;
				numa-node-id = <0>;
			};
			soc0_its15: msi-controller@1220000 {
				compatible = "arm,gic-v3-its";
				reg = <0x0 0x1220000 0x0 0x20000>;
				msi-controller;
				#msi-cells = <1>;
				numa-node-id = <0>;
			};
		};

		wdt: watchdog {
			compatible = "baikal,wdt";
			mbox-names = "wdt";
			mboxes = <&soc0_mailbox_sms 1>;
			status = "disabled";
		};
	};

	thermal-zones {
		CA75_THERMAL(0,0,1,0,1,2,3);
		CA75_THERMAL(0,1,2,4,5,6,7);
		CA75_THERMAL(0,2,3,8,9,10,11);
		CA75_THERMAL(0,3,4,12,13,14,15);
		CA75_THERMAL(0,4,5,16,17,18,19);
		CA75_THERMAL(0,5,6,20,21,22,23);
		CA75_THERMAL(0,6,7,24,25,26,27);
		CA75_THERMAL(0,7,8,28,29,30,31);
		CA75_THERMAL(0,8,9,32,33,34,35);
		CA75_THERMAL(0,9,10,36,37,38,39);
		CA75_THERMAL(0,10,11,40,41,42,43);
		CA75_THERMAL(0,11,12,44,45,46,47);
		PVT_THERMAL(0,0);
		PVT_THERMAL(0,13);
		PVT_THERMAL(0,14);
		PVT_THERMAL(0,15);
		PVT_THERMAL(0,16);
		PVT_THERMAL(0,17);
		PVT_THERMAL(0,18);
		PVT_THERMAL(0,19);
		PVT_THERMAL(0,20);
		PVT_THERMAL(0,21);
		PVT_THERMAL(0,22);
		PVT_THERMAL(0,23);
	};

	timer {
		compatible = "arm,armv8-timer";
		interrupts = <GIC_PPI 13 IRQ_TYPE_LEVEL_LOW>,
			     <GIC_PPI 14 IRQ_TYPE_LEVEL_LOW>,
			     <GIC_PPI 11 IRQ_TYPE_LEVEL_LOW>,
			     <GIC_PPI 10 IRQ_TYPE_LEVEL_LOW>;
	};
};

#ifdef ENABLE_CORESIGHT
#include "bs1000-coresight.dtsi"
#endif
